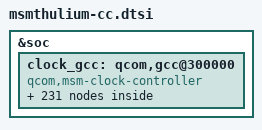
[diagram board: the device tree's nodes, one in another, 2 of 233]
/* Copyright (c) 2014, The Linux Foundation. All rights reserved.
 *
 * This program is free software; you can redistribute it and/or modify
 * it under the terms of the GNU General Public License version 2 and
 * only version 2 as published by the Free Software Foundation.
 *
 * This program is distributed in the hope that it will be useful,
 * but WITHOUT ANY WARRANTY; without even the implied warranty of
 * MERCHANTABILITY or FITNESS FOR A PARTICULAR PURPOSE.  See the
 * GNU General Public License for more details.
 */

#include <dt-bindings/clock/msm-clocks-thulium.h>
#include <dt-bindings/clock/msm-clocks-hwio-thulium.h>

&soc {
	clock_gcc: qcom,gcc@300000 {
		compatible = "qcom,msm-clock-controller";
		reg = <0x300000 0x8f010>;
		reg-names = "cc-base";
		#clock-cells = <1>;

		clock-names = "mmss_gcc_dbg_clk";
		clocks = <&clock_mmss clk_mmss_gcc_dbg_clk>;

		gcc_vdd_dig-supply = <&pmthulium_s1_corner>;
		qcom,regulator-names = "gcc_vdd_dig";

		gcc_vdd_dig: gcc_vdd_dig {
			compatible = "qcom,simple-vdd-class";
			qcom,regulators = <&pmthulium_s1_corner>;
			qcom,uV-levels =
				<RPM_REGULATOR_CORNER_NONE>,
				<RPM_REGULATOR_CORNER_SVS_SOC>,
				<RPM_REGULATOR_CORNER_SVS_SOC>,
				<RPM_REGULATOR_CORNER_NOMINAL>,
				<RPM_REGULATOR_CORNER_SUPER_TURBO>;
		};
	};
};

&clock_gcc {
	gcc_mmss_gcc_dbg_clk: gcc_mmss_gcc_dbg_clk {
		compatible = "qcom,ext-clk";
		qcom,clock-names = "mmss_gcc_dbg_clk";
		qcom,clk-flags = <0x4000>;
	};

	ce1_clk: ce1_clk {
		compatible = "qcom,rpm-clk";
		qcom,res-type = "ce";
		qcom,res-id = <0>;
		qcom,key = "KHz";
		qcom,rpm-peer = <&ce1_a_clk>;
	};

	ce1_a_clk: ce1_a_clk {
		compatible = "qcom,rpm-a-clk";
		qcom,res-type = "ce";
		qcom,res-id = <0>;
		qcom,key = "KHz";
		qcom,rpm-peer = <&ce1_clk>;
	};

	cxo_clk_src: cxo_clk_src {
		compatible = "qcom,rpm-branch-clk";
		qcom,res-type = "clk0";
		qcom,res-id = <0>;
		qcom,key = "Enab";
		qcom,rpm-peer = <&cxo_clk_src_ao>;
		qcom,rcg-init-rate = <19200000>;
	};

	cxo_clk_src_ao: cxo_clk_src_ao {
		compatible = "qcom,rpm-branch-a-clk";
		qcom,res-type = "clk0";
		qcom,res-id = <0>;
		qcom,key = "Enab";
		qcom,rpm-peer = <&cxo_clk_src>;
		qcom,rcg-init-rate = <19200000>;
	};

	pnoc_clk: pnoc_clk {
		compatible = "qcom,rpm-clk";
		qcom,res-type = "clk1";
		qcom,res-id = <0>;
		qcom,key = "KHz";
		qcom,rpm-peer = <&pnoc_a_clk>;
	};

	pnoc_a_clk: pnoc_a_clk {
		compatible = "qcom,rpm-a-clk";
		qcom,res-type = "clk1";
		qcom,res-id = <0>;
		qcom,key = "KHz";
		qcom,rpm-peer = <&pnoc_clk>;
	};

	bimc_clk: bimc_clk {
		compatible = "qcom,rpm-clk";
		qcom,res-type = "clk2";
		qcom,res-id = <0>;
		qcom,key = "KHz";
		qcom,rpm-peer = <&bimc_a_clk>;
	};

	bimc_a_clk: bimc_a_clk {
		compatible = "qcom,rpm-a-clk";
		qcom,res-type = "clk2";
		qcom,res-id = <0>;
		qcom,key = "KHz";
		qcom,rpm-peer = <&bimc_clk>;
	};

	cnoc_clk: cnoc_clk {
		compatible = "qcom,rpm-clk";
		qcom,res-type = "clk1";
		qcom,res-id = <2>;
		qcom,key = "KHz";
		qcom,rpm-peer = <&cnoc_a_clk>;
	};

	cnoc_a_clk: cnoc_a_clk {
		compatible = "qcom,rpm-a-clk";
		qcom,res-type = "clk1";
		qcom,res-id = <2>;
		qcom,key = "KHz";
		qcom,rpm-peer = <&cnoc_clk>;
	};

	snoc_clk: snoc_clk {
		compatible = "qcom,rpm-clk";
		qcom,res-type = "clk1";
		qcom,res-id = <1>;
		qcom,key = "KHz";
		qcom,rpm-peer = <&snoc_a_clk>;
	};

	snoc_a_clk: snoc_a_clk {
		compatible = "qcom,rpm-a-clk";
		qcom,res-type = "clk1";
		qcom,res-id = <1>;
		qcom,key = "KHz";
		qcom,rpm-peer = <&snoc_clk>;
	};

	aggre1_noc_clk: aggre1_noc_clk {
		compatible = "qcom,rpm-branch-clk";
		qcom,res-type = "aggr";
		qcom,res-id = <1>;
		qcom,key = "Enab";
		qcom,rpm-peer = <&aggre1_noc_a_clk>;
		qcom,rcg-init-rate = <1000>;
	};

	aggre1_noc_a_clk: aggre1_noc_a_clk {
		compatible = "qcom,rpm-branch-a-clk";
		qcom,res-type = "aggr";
		qcom,res-id = <1>;
		qcom,key = "Enab";
		qcom,rpm-peer = <&aggre1_noc_clk>;
		qcom,rcg-init-rate = <1000>;
	};

	aggre2_noc_clk: aggre2_noc_clk {
		compatible = "qcom,rpm-branch-clk";
		qcom,res-type = "aggr";
		qcom,res-id = <2>;
		qcom,key = "Enab";
		qcom,rpm-peer = <&aggre2_noc_a_clk>;
		qcom,rcg-init-rate = <1000>;
	};

	aggre2_noc_a_clk: aggre2_noc_a_clk {
		compatible = "qcom,rpm-branch-a-clk";
		qcom,res-type = "aggr";
		qcom,res-id = <2>;
		qcom,key = "Enab";
		qcom,rpm-peer = <&aggre2_noc_clk>;
		qcom,rcg-init-rate = <1000>;
	};

	bb_clk1: bb_clk1 {
		compatible = "qcom,rpm-branch-clk";
		qcom,res-type = "clka";
		qcom,res-id = <1>;
		qcom,key = "swen";
		qcom,rpm-peer = <&bb_clk1_ao>;
		qcom,rcg-init-rate = <1000>;
	};

	bb_clk1_ao: bb_clk1_ao {
		compatible = "qcom,rpm-branch-a-clk";
		qcom,res-type = "clka";
		qcom,res-id = <1>;
		qcom,key = "swen";
		qcom,rpm-peer = <&bb_clk1>;
		qcom,rcg-init-rate = <1000>;
	};

	bb_clk1_pin: bb_clk1_pin {
		compatible = "qcom,rpm-branch-clk";
		qcom,res-type = "clka";
		qcom,res-id = <1>;
		qcom,key = "pccb";
		qcom,rpm-peer = <&bb_clk1_pin_ao>;
		qcom,rcg-init-rate = <1000>;
	};

	bb_clk1_pin_ao: bb_clk1_pin_ao {
		compatible = "qcom,rpm-branch-a-clk";
		qcom,res-type = "clka";
		qcom,res-id = <1>;
		qcom,key = "pccb";
		qcom,rpm-peer = <&bb_clk1_pin>;
		qcom,rcg-init-rate = <1000>;
	};

	bb_clk2: bb_clk2 {
		compatible = "qcom,rpm-branch-clk";
		qcom,res-type = "clka";
		qcom,res-id = <2>;
		qcom,key = "swen";
		qcom,rpm-peer = <&bb_clk2_ao>;
		qcom,rcg-init-rate = <1000>;
	};

	bb_clk2_ao: bb_clk2_ao {
		compatible = "qcom,rpm-branch-a-clk";
		qcom,res-type = "clka";
		qcom,res-id = <2>;
		qcom,key = "swen";
		qcom,rpm-peer = <&bb_clk2>;
		qcom,rcg-init-rate = <1000>;
	};

	bb_clk2_pin: bb_clk2_pin {
		compatible = "qcom,rpm-branch-clk";
		qcom,res-type = "clka";
		qcom,res-id = <2>;
		qcom,key = "pccb";
		qcom,rpm-peer = <&bb_clk2_a_pin_ao>;
		qcom,rcg-init-rate = <1000>;
	};

	bb_clk2_a_pin_ao: bb_clk2_a_pin_ao {
		compatible = "qcom,rpm-branch-a-clk";
		qcom,res-type = "clka";
		qcom,res-id = <2>;
		qcom,key = "pccb";
		qcom,rpm-peer = <&bb_clk2_pin>;
		qcom,rcg-init-rate = <1000>;
	};

	bimc_msmbus_a_clk: bimc_msmbus_a_clk {
		compatible = "qcom,sw-vote-clk";
		qcom,parent = <&bimc_a_clk>;
		qcom,config-rate = <2147483647>;
	};

	bimc_msmbus_clk: bimc_msmbus_clk {
		compatible = "qcom,sw-vote-clk";
		qcom,parent = <&bimc_clk>;
		qcom,config-rate = <2147483647>;
	};

	cnoc_msmbus_a_clk: cnoc_msmbus_a_clk {
		compatible = "qcom,sw-vote-clk";
		qcom,parent = <&cnoc_a_clk>;
		qcom,config-rate = <2147483647>;
	};

	cnoc_msmbus_clk: cnoc_msmbus_clk {
		compatible = "qcom,sw-vote-clk";
		qcom,parent = <&cnoc_clk>;
		qcom,config-rate = <2147483647>;
	};

	cxo_dwc3_clk: cxo_dwc3_clk {
		compatible = "qcom,dummy-clk";
		qcom,parent = <&cxo_clk_src>;
	};

	cxo_lpm_clk: cxo_lpm_clk {
		compatible = "qcom,dummy-clk";
		qcom,parent = <&cxo_clk_src>;
	};

	cxo_otg_clk: cxo_otg_clk {
		compatible = "qcom,dummy-clk";
		qcom,parent = <&cxo_clk_src>;
	};

	cxo_pil_lpass_clk: cxo_pil_lpass_clk {
		compatible = "qcom,dummy-clk";
		qcom,parent = <&cxo_clk_src>;
	};

	div_clk1: div_clk1 {
		compatible = "qcom,rpm-branch-clk";
		qcom,res-type = "clka";
		qcom,res-id = <0xb>;
		qcom,key = "swen";
		qcom,rpm-peer = <&div_clk1_ao>;
		qcom,rcg-init-rate = <1000>;
	};

	div_clk1_ao: div_clk1_ao {
		compatible = "qcom,rpm-branch-a-clk";
		qcom,res-type = "clka";
		qcom,res-id = <0xb>;
		qcom,key = "swen";
		qcom,rpm-peer = <&div_clk1>;
		qcom,rcg-init-rate = <1000>;
	};

	div_clk2: div_clk2 {
		compatible = "qcom,rpm-branch-clk";
		qcom,res-type = "clka";
		qcom,res-id = <0xc>;
		qcom,key = "swen";
		qcom,rpm-peer = <&div_clk2_ao>;
		qcom,rcg-init-rate = <1000>;
	};

	div_clk2_ao: div_clk2_ao {
		compatible = "qcom,rpm-branch-a-clk";
		qcom,res-type = "clka";
		qcom,res-id = <0xc>;
		qcom,key = "swen";
		qcom,rpm-peer = <&div_clk2>;
		qcom,rcg-init-rate = <1000>;
	};

	div_clk3: div_clk3 {
		compatible = "qcom,rpm-branch-clk";
		qcom,res-type = "clka";
		qcom,res-id = <0xd>;
		qcom,key = "swen";
		qcom,rpm-peer = <&div_clk3_ao>;
		qcom,rcg-init-rate = <1000>;
	};

	div_clk3_ao: div_clk3_ao {
		compatible = "qcom,rpm-branch-a-clk";
		qcom,res-type = "clka";
		qcom,res-id = <0xd>;
		qcom,key = "swen";
		qcom,rpm-peer = <&div_clk3>;
		qcom,rcg-init-rate = <1000>;
	};

	ipa_clk: ipa_clk {
		compatible = "qcom,rpm-clk";
		qcom,res-type = "ipa";
		qcom,res-id = <0>;
		qcom,key = "KHz";
		qcom,rpm-peer = <&ipa_a_clk>;
	};

	ipa_a_clk: ipa_a_clk {
		compatible = "qcom,rpm-a-clk";
		qcom,res-type = "ipa";
		qcom,res-id = <0>;
		qcom,key = "KHz";
		qcom,rpm-peer = <&ipa_clk>;
	};

	ln_bb_clk: ln_bb_clk {
		compatible = "qcom,rpm-branch-clk";
		qcom,res-type = "clka";
		qcom,res-id = <8>;
		qcom,key = "swen";
		qcom,rpm-peer = <&ln_bb_a_clk>;
		qcom,rcg-init-rate = <1000>;
	};

	ln_bb_a_clk: ln_bb_a_clk {
		compatible = "qcom,rpm-branch-a-clk";
		qcom,res-type = "clka";
		qcom,res-id = <8>;
		qcom,key = "swen";
		qcom,rpm-peer = <&ln_bb_clk>;
		qcom,rcg-init-rate = <1000>;
	};

	mcd_ce1_clk: mcd_ce1_clk {
		compatible = "qcom,sw-vote-clk";
		qcom,parent = <&ce1_clk>;
		qcom,config-rate = <85710000>;
	};

	pnoc_keepalive_a_clk: pnoc_keepalive_a_clk {
		compatible = "qcom,sw-vote-clk";
		qcom,parent = <&pnoc_a_clk>;
		qcom,always-on;
		qcom,config-rate = <19200000>;
	};

	pnoc_msmbus_a_clk: pnoc_msmbus_a_clk {
		compatible = "qcom,sw-vote-clk";
		qcom,parent = <&pnoc_a_clk>;
		qcom,config-rate = <2147483647>;
	};

	pnoc_msmbus_clk: pnoc_msmbus_clk {
		compatible = "qcom,sw-vote-clk";
		qcom,parent = <&pnoc_clk>;
		qcom,config-rate = <2147483647>;
	};

	pnoc_pm_clk: pnoc_pm_clk {
		compatible = "qcom,sw-vote-clk";
		qcom,parent = <&pnoc_clk>;
		qcom,config-rate = <2147483647>;
	};

	pnoc_sps_clk: pnoc_sps_clk {
		compatible = "qcom,sw-vote-clk";
		qcom,parent = <&pnoc_clk>;
		qcom,config-rate = <0>;
	};

	qcedev_ce1_clk: qcedev_ce1_clk {
		compatible = "qcom,sw-vote-clk";
		qcom,parent = <&ce1_clk>;
		qcom,config-rate = <85710000>;
	};

	qcrypto_ce1_clk: qcrypto_ce1_clk {
		compatible = "qcom,sw-vote-clk";
		qcom,parent = <&ce1_clk>;
		qcom,config-rate = <85710000>;
	};

	qdss_clk: qdss_clk {
		compatible = "qcom,rpm-clk";
		qcom,res-type = "clk0";
		qcom,res-id = <1>;
		qcom,key = "STAT";
		qcom,rpm-peer = <&qdss_a_clk>;
	};

	qdss_a_clk: qdss_a_clk {
		compatible = "qcom,rpm-a-clk";
		qcom,res-type = "clk0";
		qcom,res-id = <1>;
		qcom,key = "STAT";
		qcom,rpm-peer = <&qdss_clk>;
	};

	qseecom_ce1_clk: qseecom_ce1_clk {
		compatible = "qcom,sw-vote-clk";
		qcom,parent = <&ce1_clk>;
		qcom,config-rate = <85710000>;
	};

	rf_clk1: rf_clk1 {
		compatible = "qcom,rpm-branch-clk";
		qcom,res-type = "clka";
		qcom,res-id = <4>;
		qcom,key = "swen";
		qcom,rpm-peer = <&rf_clk1_ao>;
		qcom,rcg-init-rate = <1000>;
	};

	rf_clk1_ao: rf_clk1_ao {
		compatible = "qcom,rpm-branch-a-clk";
		qcom,res-type = "clka";
		qcom,res-id = <4>;
		qcom,key = "swen";
		qcom,rpm-peer = <&rf_clk1>;
		qcom,rcg-init-rate = <1000>;
	};

	rf_clk1_pin: rf_clk1_pin {
		compatible = "qcom,rpm-branch-clk";
		qcom,res-type = "clka";
		qcom,res-id = <4>;
		qcom,key = "pccb";
		qcom,rpm-peer = <&rf_clk1_a_pin_ao>;
		qcom,rcg-init-rate = <1000>;
	};

	rf_clk1_a_pin_ao: rf_clk1_a_pin_ao {
		compatible = "qcom,rpm-branch-a-clk";
		qcom,res-type = "clka";
		qcom,res-id = <4>;
		qcom,key = "pccb";
		qcom,rpm-peer = <&rf_clk1_pin>;
		qcom,rcg-init-rate = <1000>;
	};

	rf_clk2: rf_clk2 {
		compatible = "qcom,rpm-branch-clk";
		qcom,res-type = "clka";
		qcom,res-id = <5>;
		qcom,key = "swen";
		qcom,rpm-peer = <&rf_clk2_ao>;
		qcom,rcg-init-rate = <1000>;
	};

	rf_clk2_ao: rf_clk2_ao {
		compatible = "qcom,rpm-branch-a-clk";
		qcom,res-type = "clka";
		qcom,res-id = <5>;
		qcom,key = "swen";
		qcom,rpm-peer = <&rf_clk2>;
		qcom,rcg-init-rate = <1000>;
	};

	rf_clk2_pin: rf_clk2_pin {
		compatible = "qcom,rpm-branch-clk";
		qcom,res-type = "clka";
		qcom,res-id = <5>;
		qcom,key = "pccb";
		qcom,rpm-peer = <&rf_clk2_a_pin_ao>;
		qcom,rcg-init-rate = <1000>;
	};

	rf_clk2_a_pin_ao: rf_clk2_a_pin_ao {
		compatible = "qcom,rpm-branch-a-clk";
		qcom,res-type = "clka";
		qcom,res-id = <5>;
		qcom,key = "pccb";
		qcom,rpm-peer = <&rf_clk2_pin>;
		qcom,rcg-init-rate = <1000>;
	};

	scm_ce1_clk: scm_ce1_clk {
		compatible = "qcom,sw-vote-clk";
		qcom,parent = <&ce1_clk>;
		qcom,config-rate = <85710000>;
	};

	snoc_msmbus_a_clk: snoc_msmbus_a_clk {
		compatible = "qcom,sw-vote-clk";
		qcom,parent = <&snoc_a_clk>;
		qcom,config-rate = <2147483647>;
	};

	snoc_msmbus_clk: snoc_msmbus_clk {
		compatible = "qcom,sw-vote-clk";
		qcom,parent = <&snoc_clk>;
		qcom,config-rate = <2147483647>;
	};

	gcc_ce1_ahb_m_clk: gcc_ce1_ahb_m_clk {
		compatible = "qcom,dummy-clk";
	};

	gcc_ce1_axi_m_clk: gcc_ce1_axi_m_clk {
		compatible = "qcom,dummy-clk";
	};

	gcc_mmss_bimc_gfx_m_clk: gcc_mmss_bimc_gfx_m_clk {
		compatible = "qcom,dummy-clk";
	};

	gpll0: gpll0 {
		compatible = "qcom,sleep-active-pll";
		qcom,en-offset = <GCC_APCS_GPLL_ENA_VOTE>;
		qcom,en-bit = <0>;
		qcom,status-offset = <GCC_GPLL0_MODE>;
		qcom,status-bit = <30>;
		qcom,peer = <&gpll0_ao>;
		qcom,pll-config-rate = <600000000>;
		qcom,parent = <&cxo_clk_src>;
	};

	gpll0_ao: gpll0_ao {
		compatible = "qcom,active-only-pll";
		qcom,en-offset = <GCC_APCS_GPLL_ENA_VOTE>;
		qcom,en-bit = <0>;
		qcom,status-offset = <GCC_GPLL0_MODE>;
		qcom,status-bit = <30>;
		qcom,peer = <&gpll0>;
		qcom,pll-config-rate = <600000000>;
		qcom,parent = <&cxo_clk_src_ao>;
	};

	gpll0_out_main: gpll0_out_main {
		compatible = "qcom,ext-clk";
		qcom,parent = <&gpll0>;
	};

	gpll4: gpll4 {
		compatible = "qcom,votable-pll";
		qcom,en-offset = <GCC_APCS_GPLL_ENA_VOTE>;
		qcom,en-bit = <4>;
		qcom,status-offset = <GCC_GPLL4_MODE>;
		qcom,status-bit = <30>;
		qcom,pll-config-rate = <1536000000>;
		qcom,parent = <&cxo_clk_src>;
		qcom,supply-group = <&gcc_vdd_dig>;
		qcom,clk-fmax =
			<FMAX_LOWER 400000000>,
			<FMAX_LOW 800000000>,
			<FMAX_NOM 1600000000>,
			<FMAX_TURBO 1600000000>;
	};

	gpll4_out_main: gpll4_out_main {
		compatible = "qcom,ext-clk";
		qcom,parent = <&gpll4>;
	};

	ufs_axi_clk_src {
		qcom,freq-tbl =
			< 100000000 6 0 0 0 &gpll0_out_main>,
			< 200000000 3 0 0 0 &gpll0_out_main>,
			< 240000000 2 50 0 0 &gpll0_out_main>;
	};

	ufs_axi_clk_src: ufs_axi_clk_src {
		compatible = "qcom,rcg-mn";
		qcom,base-offset = <GCC_UFS_AXI_CMD_RCGR>;
		qcom,parents =
			<    0 &cxo_clk_src>,
			<    1 &gpll0_out_main>;
		qcom,supply-group = <&gcc_vdd_dig>;
		qcom,clk-fmax =
			<FMAX_LOWER 19200000>,
			<FMAX_LOW 100000000>,
			<FMAX_NOM 200000000>,
			<FMAX_TURBO 240000000>;
	};

	pcie_aux_clk_src {
		qcom,freq-tbl =
			<   1010526 19 0 0 0 &cxo_clk_src>;
	};

	pcie_aux_clk_src: pcie_aux_clk_src {
		compatible = "qcom,rcg-mn";
		qcom,base-offset = <GCC_PCIE_AUX_CMD_RCGR>;
		qcom,parents =
			<    0 &cxo_clk_src>;
		qcom,supply-group = <&gcc_vdd_dig>;
		qcom,clk-fmax =
			<FMAX_LOWER 1011000>,
			<FMAX_LOW 1011000>,
			<FMAX_NOM 1011000>,
			<FMAX_TURBO 1011000>;
	};

	usb30_master_clk_src {
		qcom,freq-tbl =
			< 125000000 1 0 5 24 &gpll0_out_main>;
	};

	usb30_master_clk_src: usb30_master_clk_src {
		compatible = "qcom,rcg-mn";
		qcom,base-offset = <GCC_USB30_MASTER_CMD_RCGR>;
		qcom,parents =
			<    0 &cxo_clk_src>,
			<    1 &gpll0_out_main>;
		qcom,supply-group = <&gcc_vdd_dig>;
		qcom,clk-fmax =
			<FMAX_LOWER 60000000>,
			<FMAX_LOW 125000000>,
			<FMAX_NOM 125000000>,
			<FMAX_TURBO 125000000>;
	};

	usb20_master_clk_src {
		qcom,freq-tbl =
			< 120000000 5 0 0 0 &gpll0_out_main>;
	};

	usb20_master_clk_src: usb20_master_clk_src {
		compatible = "qcom,rcg-mn";
		qcom,base-offset = <GCC_USB20_MASTER_CMD_RCGR>;
		qcom,parents =
			<    0 &cxo_clk_src>,
			<    1 &gpll0_out_main>;
		qcom,supply-group = <&gcc_vdd_dig>;
		qcom,clk-fmax =
			<FMAX_LOWER 19200000>,
			<FMAX_LOW 60000000>,
			<FMAX_NOM 120000000>,
			<FMAX_TURBO 120000000>;
	};

	ufs_ice_core_clk_src {
		qcom,freq-tbl =
			< 19200000 1 0 0 0 &cxo_clk_src>,
			< 150000000 4 0 0 0 &gpll0_out_main>,
			< 300000000 2 0 0 0 &gpll0_out_main>;
	};

	ufs_ice_core_clk_src: ufs_ice_core_clk_src {
		compatible = "qcom,rcg-hid";
		qcom,base-offset = <GCC_UFS_ICE_CORE_CMD_RCGR>;
		qcom,parents =
			<    0 &cxo_clk_src>,
			<    1 &gpll0_out_main>;
		qcom,supply-group = <&gcc_vdd_dig>;
		qcom,clk-fmax =
			<FMAX_LOWER 19200000>,
			<FMAX_LOW 150000000>,
			<FMAX_NOM 300000000>,
			<FMAX_TURBO 300000000>;
	};

	blsp1_qup1_i2c_apps_clk_src {
		qcom,freq-tbl =
			<  19200000 1 0 0 0 &cxo_clk_src>,
			<  50000000 12 0 0 0 &gpll0_out_main>;
	};

	blsp1_qup1_i2c_apps_clk_src: blsp1_qup1_i2c_apps_clk_src {
		compatible = "qcom,rcg-hid";
		qcom,base-offset = <GCC_BLSP1_QUP1_I2C_APPS_CMD_RCGR>;
		qcom,parents =
			<    0 &cxo_clk_src>,
			<    1 &gpll0_out_main>;
		qcom,supply-group = <&gcc_vdd_dig>;
		qcom,clk-fmax =
			<FMAX_LOWER 19200000>,
			<FMAX_LOW 50000000>,
			<FMAX_NOM 50000000>,
			<FMAX_TURBO 50000000>;
	};

	blsp1_qup1_spi_apps_clk_src {
		qcom,freq-tbl =
			<    960000 10 0 1 2 &cxo_clk_src>,
			<   4800000 4 0 0 0 &cxo_clk_src>,
			<   9600000 2 0 0 0 &cxo_clk_src>,
			<  15000000 10 0 1 4 &gpll0_out_main>,
			<  25000000 12 0 1 2 &gpll0_out_main>,
			<  50000000 12 0 0 0 &gpll0_out_main>;
	};

	blsp1_qup1_spi_apps_clk_src: blsp1_qup1_spi_apps_clk_src {
		compatible = "qcom,rcg-mn";
		qcom,base-offset = <GCC_BLSP1_QUP1_SPI_APPS_CMD_RCGR>;
		qcom,parents =
			<    0 &cxo_clk_src>,
			<    1 &gpll0_out_main>;
		qcom,supply-group = <&gcc_vdd_dig>;
		qcom,clk-fmax =
			<FMAX_LOWER 19200000>,
			<FMAX_LOW 25000000>,
			<FMAX_NOM 50000000>,
			<FMAX_TURBO 50000000>;
	};

	blsp1_qup2_i2c_apps_clk_src {
		qcom,freq-tbl =
			<   19200000 1 0 0 0 &cxo_clk_src>,
			<  50000000 12 0 0 0 &gpll0_out_main>;
	};

	blsp1_qup2_i2c_apps_clk_src: blsp1_qup2_i2c_apps_clk_src {
		compatible = "qcom,rcg-hid";
		qcom,base-offset = <GCC_BLSP1_QUP2_I2C_APPS_CMD_RCGR>;
		qcom,parents =
			<    0 &cxo_clk_src>,
			<    1 &gpll0_out_main>;
		qcom,supply-group = <&gcc_vdd_dig>;
		qcom,clk-fmax =
			<FMAX_LOWER 19200000>,
			<FMAX_LOW 50000000>,
			<FMAX_NOM 50000000>,
			<FMAX_TURBO 50000000>;
	};

	blsp1_qup2_spi_apps_clk_src {
		qcom,freq-tbl =
			<    960000 10 0 1 2 &cxo_clk_src>,
			<   4800000 4 0 0 0 &cxo_clk_src>,
			<   9600000 2 0 0 0 &cxo_clk_src>,
			<  15000000 10 0 1 4 &gpll0_out_main>,
			<  25000000 12 0 1 2 &gpll0_out_main>,
			<  50000000 12 0 0 0 &gpll0_out_main>;
	};

	blsp1_qup2_spi_apps_clk_src: blsp1_qup2_spi_apps_clk_src {
		compatible = "qcom,rcg-mn";
		qcom,base-offset = <GCC_BLSP1_QUP2_SPI_APPS_CMD_RCGR>;
		qcom,parents =
			<    0 &cxo_clk_src>,
			<    1 &gpll0_out_main>;
		qcom,supply-group = <&gcc_vdd_dig>;
		qcom,clk-fmax =
			<FMAX_LOWER 19200000>,
			<FMAX_LOW 25000000>,
			<FMAX_NOM 50000000>,
			<FMAX_TURBO 50000000>;
	};

	blsp1_qup3_i2c_apps_clk_src {
		qcom,freq-tbl =
			<   19200000 1 0 0 0 &cxo_clk_src>,
			<  50000000 12 0 0 0 &gpll0_out_main>;
	};

	blsp1_qup3_i2c_apps_clk_src: blsp1_qup3_i2c_apps_clk_src {
		compatible = "qcom,rcg-hid";
		qcom,base-offset = <GCC_BLSP1_QUP3_I2C_APPS_CMD_RCGR>;
		qcom,parents =
			<    0 &cxo_clk_src>,
			<    1 &gpll0_out_main>;
		qcom,supply-group = <&gcc_vdd_dig>;
		qcom,clk-fmax =
			<FMAX_LOWER 19200000>,
			<FMAX_LOW 50000000>,
			<FMAX_NOM 50000000>,
			<FMAX_TURBO 50000000>;
	};

	blsp1_qup3_spi_apps_clk_src {
		qcom,freq-tbl =
			<    960000 10 0 1 2 &cxo_clk_src>,
			<   4800000 4 0 0 0 &cxo_clk_src>,
			<   9600000 2 0 0 0 &cxo_clk_src>,
			<  15000000 10 0 1 4 &gpll0_out_main>,
			<  25000000 12 0 1 2 &gpll0_out_main>,
			<  50000000 12 0 0 0 &gpll0_out_main>;
	};

	blsp1_qup3_spi_apps_clk_src: blsp1_qup3_spi_apps_clk_src {
		compatible = "qcom,rcg-mn";
		qcom,base-offset = <GCC_BLSP1_QUP3_SPI_APPS_CMD_RCGR>;
		qcom,parents =
			<    0 &cxo_clk_src>,
			<    1 &gpll0_out_main>;
		qcom,supply-group = <&gcc_vdd_dig>;
		qcom,clk-fmax =
			<FMAX_LOWER 19200000>,
			<FMAX_LOW 25000000>,
			<FMAX_NOM 50000000>,
			<FMAX_TURBO 50000000>;
	};

	blsp1_qup4_i2c_apps_clk_src {
		qcom,freq-tbl =
			<   19200000 1 0 0 0 &cxo_clk_src>,
			<  50000000 12 0 0 0 &gpll0_out_main>;
	};

	blsp1_qup4_i2c_apps_clk_src: blsp1_qup4_i2c_apps_clk_src {
		compatible = "qcom,rcg-hid";
		qcom,base-offset = <GCC_BLSP1_QUP4_I2C_APPS_CMD_RCGR>;
		qcom,parents =
			<    0 &cxo_clk_src>,
			<    1 &gpll0_out_main>;
		qcom,supply-group = <&gcc_vdd_dig>;
		qcom,clk-fmax =
			<FMAX_LOWER 19200000>,
			<FMAX_LOW 50000000>,
			<FMAX_NOM 50000000>,
			<FMAX_TURBO 50000000>;
	};

	blsp1_qup4_spi_apps_clk_src {
		qcom,freq-tbl =
			<    960000 10 0 1 2 &cxo_clk_src>,
			<   4800000 4 0 0 0 &cxo_clk_src>,
			<   9600000 2 0 0 0 &cxo_clk_src>,
			<  15000000 10 0 1 4 &gpll0_out_main>,
			<  25000000 12 0 1 2 &gpll0_out_main>,
			<  50000000 12 0 0 0 &gpll0_out_main>;
	};

	blsp1_qup4_spi_apps_clk_src: blsp1_qup4_spi_apps_clk_src {
		compatible = "qcom,rcg-mn";
		qcom,base-offset = <GCC_BLSP1_QUP4_SPI_APPS_CMD_RCGR>;
		qcom,parents =
			<    0 &cxo_clk_src>,
			<    1 &gpll0_out_main>;
		qcom,supply-group = <&gcc_vdd_dig>;
		qcom,clk-fmax =
			<FMAX_LOWER 19200000>,
			<FMAX_LOW 25000000>,
			<FMAX_NOM 50000000>,
			<FMAX_TURBO 50000000>;
	};

	blsp1_qup5_i2c_apps_clk_src {
		qcom,freq-tbl =
			<   19200000 1 0 0 0 &cxo_clk_src>,
			<  50000000 12 0 0 0 &gpll0_out_main>;
	};

	blsp1_qup5_i2c_apps_clk_src: blsp1_qup5_i2c_apps_clk_src {
		compatible = "qcom,rcg-hid";
		qcom,base-offset = <GCC_BLSP1_QUP5_I2C_APPS_CMD_RCGR>;
		qcom,parents =
			<    0 &cxo_clk_src>,
			<    1 &gpll0_out_main>;
		qcom,supply-group = <&gcc_vdd_dig>;
		qcom,clk-fmax =
			<FMAX_LOWER 19200000>,
			<FMAX_LOW 50000000>,
			<FMAX_NOM 50000000>,
			<FMAX_TURBO 50000000>;
	};

	blsp1_qup5_spi_apps_clk_src {
		qcom,freq-tbl =
			<    960000 10 0 1 2 &cxo_clk_src>,
			<   4800000 4 0 0 0 &cxo_clk_src>,
			<   9600000 2 0 0 0 &cxo_clk_src>,
			<  15000000 10 0 1 4 &gpll0_out_main>,
			<  25000000 12 0 1 2 &gpll0_out_main>,
			<  50000000 12 0 0 0 &gpll0_out_main>;
	};

	blsp1_qup5_spi_apps_clk_src: blsp1_qup5_spi_apps_clk_src {
		compatible = "qcom,rcg-mn";
		qcom,base-offset = <GCC_BLSP1_QUP5_SPI_APPS_CMD_RCGR>;
		qcom,parents =
			<    0 &cxo_clk_src>,
			<    1 &gpll0_out_main>;
		qcom,supply-group = <&gcc_vdd_dig>;
		qcom,clk-fmax =
			<FMAX_LOWER 19200000>,
			<FMAX_LOW 25000000>,
			<FMAX_NOM 50000000>,
			<FMAX_TURBO 50000000>;
	};

	blsp1_qup6_i2c_apps_clk_src {
		qcom,freq-tbl =
			<   19200000 1 0 0 0 &cxo_clk_src>,
			<  50000000 12 0 0 0 &gpll0_out_main>;
	};

	blsp1_qup6_i2c_apps_clk_src: blsp1_qup6_i2c_apps_clk_src {
		compatible = "qcom,rcg-hid";
		qcom,base-offset = <GCC_BLSP1_QUP6_I2C_APPS_CMD_RCGR>;
		qcom,parents =
			<    0 &cxo_clk_src>,
			<    1 &gpll0_out_main>;
		qcom,supply-group = <&gcc_vdd_dig>;
		qcom,clk-fmax =
			<FMAX_LOWER 19200000>,
			<FMAX_LOW 50000000>,
			<FMAX_NOM 50000000>,
			<FMAX_TURBO 50000000>;
	};

	blsp1_qup6_spi_apps_clk_src {
		qcom,freq-tbl =
			<    960000 10 0 1 2 &cxo_clk_src>,
			<   4800000 4 0 0 0 &cxo_clk_src>,
			<   9600000 2 0 0 0 &cxo_clk_src>,
			<  15000000 10 0 1 4 &gpll0_out_main>,
			<  25000000 12 0 1 2 &gpll0_out_main>,
			<  50000000 12 0 0 0 &gpll0_out_main>;
	};

	blsp1_qup6_spi_apps_clk_src: blsp1_qup6_spi_apps_clk_src {
		compatible = "qcom,rcg-mn";
		qcom,base-offset = <GCC_BLSP1_QUP6_SPI_APPS_CMD_RCGR>;
		qcom,parents =
			<    0 &cxo_clk_src>,
			<    1 &gpll0_out_main>;
		qcom,supply-group = <&gcc_vdd_dig>;
		qcom,clk-fmax =
			<FMAX_LOWER 19200000>,
			<FMAX_LOW 25000000>,
			<FMAX_NOM 50000000>,
			<FMAX_TURBO 50000000>;
	};

	blsp1_uart1_apps_clk_src {
		qcom,freq-tbl =
			<   3686400 1 0 96 15625 &gpll0_out_main>,
			<   7372800 1 0 192 15625 &gpll0_out_main>,
			<  14745600 1 0 384 15625 &gpll0_out_main>,
			<  16000000 5 0 2 15 &gpll0_out_main>,
			<  24000000 5 0 1 5 &gpll0_out_main>,
			<  32000000 1 0 4 75 &gpll0_out_main>,
			<  40000000 15 0 0 0 &gpll0_out_main>,
			<  46400000 1 0 29 375 &gpll0_out_main>,
			<  48000000 12 50 0 0 &gpll0_out_main>,
			<  51200000 1 0 32 375 &gpll0_out_main>,
			<  56000000 1 0 7 75 &gpll0_out_main>,
			<  58982400 1 0 1536 15625 &gpll0_out_main>,
			<  60000000 10 0 0 0 &gpll0_out_main>,
			<  63160000 9 50 0 0 &gpll0_out_main>;
	};

	blsp1_uart1_apps_clk_src: blsp1_uart1_apps_clk_src {
		compatible = "qcom,rcg-mn";
		qcom,base-offset = <GCC_BLSP1_UART1_APPS_CMD_RCGR>;
		qcom,parents =
			<    0 &cxo_clk_src>,
			<    1 &gpll0_out_main>;
		qcom,supply-group = <&gcc_vdd_dig>;
		qcom,clk-fmax =
			<FMAX_LOWER 19200000>,
			<FMAX_LOW 31580000>,
			<FMAX_NOM 63160000>,
			<FMAX_TURBO 63160000>;
	};

	blsp1_uart2_apps_clk_src {
		qcom,freq-tbl =
			<   3686400 1 0 96 15625 &gpll0_out_main>,
			<   7372800 1 0 192 15625 &gpll0_out_main>,
			<  14745600 1 0 384 15625 &gpll0_out_main>,
			<  16000000 5 0 2 15 &gpll0_out_main>,
			<  24000000 5 0 1 5 &gpll0_out_main>,
			<  32000000 1 0 4 75 &gpll0_out_main>,
			<  40000000 15 0 0 0 &gpll0_out_main>,
			<  46400000 1 0 29 375 &gpll0_out_main>,
			<  48000000 12 50 0 0 &gpll0_out_main>,
			<  51200000 1 0 32 375 &gpll0_out_main>,
			<  56000000 1 0 7 75 &gpll0_out_main>,
			<  58982400 1 0 1536 15625 &gpll0_out_main>,
			<  60000000 10 0 0 0 &gpll0_out_main>,
			<  63160000 9 50 0 0 &gpll0_out_main>;
	};

	blsp1_uart2_apps_clk_src: blsp1_uart2_apps_clk_src {
		compatible = "qcom,rcg-mn";
		qcom,base-offset = <GCC_BLSP1_UART2_APPS_CMD_RCGR>;
		qcom,parents =
			<    0 &cxo_clk_src>,
			<    1 &gpll0_out_main>;
		qcom,supply-group = <&gcc_vdd_dig>;
		qcom,clk-fmax =
			<FMAX_LOWER 19200000>,
			<FMAX_LOW 31580000>,
			<FMAX_NOM 63160000>,
			<FMAX_TURBO 63160000>;
	};

	blsp1_uart3_apps_clk_src {
		qcom,freq-tbl =
			<   3686400 1 0 96 15625 &gpll0_out_main>,
			<   7372800 1 0 192 15625 &gpll0_out_main>,
			<  14745600 1 0 384 15625 &gpll0_out_main>,
			<  16000000 5 0 2 15 &gpll0_out_main>,
			<  24000000 5 0 1 5 &gpll0_out_main>,
			<  32000000 1 0 4 75 &gpll0_out_main>,
			<  40000000 15 0 0 0 &gpll0_out_main>,
			<  46400000 1 0 29 375 &gpll0_out_main>,
			<  48000000 12 50 0 0 &gpll0_out_main>,
			<  51200000 1 0 32 375 &gpll0_out_main>,
			<  56000000 1 0 7 75 &gpll0_out_main>,
			<  58982400 1 0 1536 15625 &gpll0_out_main>,
			<  60000000 10 0 0 0 &gpll0_out_main>,
			<  63160000 9 50 0 0 &gpll0_out_main>;
	};

	blsp1_uart3_apps_clk_src: blsp1_uart3_apps_clk_src {
		compatible = "qcom,rcg-mn";
		qcom,base-offset = <GCC_BLSP1_UART3_APPS_CMD_RCGR>;
		qcom,parents =
			<    0 &cxo_clk_src>,
			<    1 &gpll0_out_main>;
		qcom,supply-group = <&gcc_vdd_dig>;
		qcom,clk-fmax =
			<FMAX_LOWER 19200000>,
			<FMAX_LOW 31580000>,
			<FMAX_NOM 63160000>,
			<FMAX_TURBO 63160000>;
	};

	blsp1_uart4_apps_clk_src {
		qcom,freq-tbl =
			<   3686400 1 0 96 15625 &gpll0_out_main>,
			<   7372800 1 0 192 15625 &gpll0_out_main>,
			<  14745600 1 0 384 15625 &gpll0_out_main>,
			<  16000000 5 0 2 15 &gpll0_out_main>,
			<  24000000 5 0 1 5 &gpll0_out_main>,
			<  32000000 1 0 4 75 &gpll0_out_main>,
			<  40000000 15 0 0 0 &gpll0_out_main>,
			<  46400000 1 0 29 375 &gpll0_out_main>,
			<  48000000 12 50 0 0 &gpll0_out_main>,
			<  51200000 1 0 32 375 &gpll0_out_main>,
			<  56000000 1 0 7 75 &gpll0_out_main>,
			<  58982400 1 0 1536 15625 &gpll0_out_main>,
			<  60000000 10 0 0 0 &gpll0_out_main>,
			<  63160000 9 50 0 0 &gpll0_out_main>;
	};

	blsp1_uart4_apps_clk_src: blsp1_uart4_apps_clk_src {
		compatible = "qcom,rcg-mn";
		qcom,base-offset = <GCC_BLSP1_UART4_APPS_CMD_RCGR>;
		qcom,parents =
			<    0 &cxo_clk_src>,
			<    1 &gpll0_out_main>;
		qcom,supply-group = <&gcc_vdd_dig>;
		qcom,clk-fmax =
			<FMAX_LOWER 19200000>,
			<FMAX_LOW 31580000>,
			<FMAX_NOM 63160000>,
			<FMAX_TURBO 63160000>;
	};

	blsp1_uart5_apps_clk_src {
		qcom,freq-tbl =
			<   3686400 1 0 96 15625 &gpll0_out_main>,
			<   7372800 1 0 192 15625 &gpll0_out_main>,
			<  14745600 1 0 384 15625 &gpll0_out_main>,
			<  16000000 5 0 2 15 &gpll0_out_main>,
			<  24000000 5 0 1 5 &gpll0_out_main>,
			<  32000000 1 0 4 75 &gpll0_out_main>,
			<  40000000 15 0 0 0 &gpll0_out_main>,
			<  46400000 1 0 29 375 &gpll0_out_main>,
			<  48000000 12 50 0 0 &gpll0_out_main>,
			<  51200000 1 0 32 375 &gpll0_out_main>,
			<  56000000 1 0 7 75 &gpll0_out_main>,
			<  58982400 1 0 1536 15625 &gpll0_out_main>,
			<  60000000 10 0 0 0 &gpll0_out_main>,
			<  63160000 9 50 0 0 &gpll0_out_main>;
	};

	blsp1_uart5_apps_clk_src: blsp1_uart5_apps_clk_src {
		compatible = "qcom,rcg-mn";
		qcom,base-offset = <GCC_BLSP1_UART5_APPS_CMD_RCGR>;
		qcom,parents =
			<    0 &cxo_clk_src>,
			<    1 &gpll0_out_main>;
		qcom,supply-group = <&gcc_vdd_dig>;
		qcom,clk-fmax =
			<FMAX_LOWER 19200000>,
			<FMAX_LOW 31580000>,
			<FMAX_NOM 63160000>,
			<FMAX_TURBO 63160000>;
	};

	blsp1_uart6_apps_clk_src {
		qcom,freq-tbl =
			<   3686400 1 0 96 15625 &gpll0_out_main>,
			<   7372800 1 0 192 15625 &gpll0_out_main>,
			<  14745600 1 0 384 15625 &gpll0_out_main>,
			<  16000000 5 0 2 15 &gpll0_out_main>,
			<  24000000 5 0 1 5 &gpll0_out_main>,
			<  32000000 1 0 4 75 &gpll0_out_main>,
			<  40000000 15 0 0 0 &gpll0_out_main>,
			<  46400000 1 0 29 375 &gpll0_out_main>,
			<  48000000 12 50 0 0 &gpll0_out_main>,
			<  51200000 1 0 32 375 &gpll0_out_main>,
			<  56000000 1 0 7 75 &gpll0_out_main>,
			<  58982400 1 0 1536 15625 &gpll0_out_main>,
			<  60000000 10 0 0 0 &gpll0_out_main>,
			<  63160000 9 50 0 0 &gpll0_out_main>;
	};

	blsp1_uart6_apps_clk_src: blsp1_uart6_apps_clk_src {
		compatible = "qcom,rcg-mn";
		qcom,base-offset = <GCC_BLSP1_UART6_APPS_CMD_RCGR>;
		qcom,parents =
			<    0 &cxo_clk_src>,
			<    1 &gpll0_out_main>;
		qcom,supply-group = <&gcc_vdd_dig>;
		qcom,clk-fmax =
			<FMAX_LOWER 19200000>,
			<FMAX_LOW 31580000>,
			<FMAX_NOM 63160000>,
			<FMAX_TURBO 63160000>;
	};

	blsp2_qup1_i2c_apps_clk_src {
		qcom,freq-tbl =
			<   19200000 1 0 0 0 &cxo_clk_src>,
			<  50000000 12 0 0 0 &gpll0_out_main>;
	};

	blsp2_qup1_i2c_apps_clk_src: blsp2_qup1_i2c_apps_clk_src {
		compatible = "qcom,rcg-hid";
		qcom,base-offset = <GCC_BLSP2_QUP1_I2C_APPS_CMD_RCGR>;
		qcom,parents =
			<    0 &cxo_clk_src>,
			<    1 &gpll0_out_main>;
		qcom,supply-group = <&gcc_vdd_dig>;
		qcom,clk-fmax =
			<FMAX_LOWER 19200000>,
			<FMAX_LOW 50000000>,
			<FMAX_NOM 50000000>,
			<FMAX_TURBO 50000000>;
	};

	blsp2_qup1_spi_apps_clk_src {
		qcom,freq-tbl =
			<    960000 10 0 1 2 &cxo_clk_src>,
			<   4800000 4 0 0 0 &cxo_clk_src>,
			<   9600000 2 0 0 0 &cxo_clk_src>,
			<  15000000 10 0 1 4 &gpll0_out_main>,
			<  25000000 12 0 1 2 &gpll0_out_main>,
			<  50000000 12 0 0 0 &gpll0_out_main>;
	};

	blsp2_qup1_spi_apps_clk_src: blsp2_qup1_spi_apps_clk_src {
		compatible = "qcom,rcg-mn";
		qcom,base-offset = <GCC_BLSP2_QUP1_SPI_APPS_CMD_RCGR>;
		qcom,parents =
			<    0 &cxo_clk_src>,
			<    1 &gpll0_out_main>;
		qcom,supply-group = <&gcc_vdd_dig>;
		qcom,clk-fmax =
			<FMAX_LOWER 19200000>,
			<FMAX_LOW 25000000>,
			<FMAX_NOM 50000000>,
			<FMAX_TURBO 50000000>;
	};

	blsp2_qup2_i2c_apps_clk_src {
		qcom,freq-tbl =
			<   19200000 1 0 0 0 &cxo_clk_src>,
			<  50000000 12 0 0 0 &gpll0_out_main>;
	};

	blsp2_qup2_i2c_apps_clk_src: blsp2_qup2_i2c_apps_clk_src {
		compatible = "qcom,rcg-hid";
		qcom,base-offset = <GCC_BLSP2_QUP2_I2C_APPS_CMD_RCGR>;
		qcom,parents =
			<    0 &cxo_clk_src>,
			<    1 &gpll0_out_main>;
		qcom,supply-group = <&gcc_vdd_dig>;
		qcom,clk-fmax =
			<FMAX_LOWER 19200000>,
			<FMAX_LOW 50000000>,
			<FMAX_NOM 50000000>,
			<FMAX_TURBO 50000000>;
	};

	blsp2_qup2_spi_apps_clk_src {
		qcom,freq-tbl =
			<    960000 10 0 1 2 &cxo_clk_src>,
			<   4800000 4 0 0 0 &cxo_clk_src>,
			<   9600000 2 0 0 0 &cxo_clk_src>,
			<  15000000 10 0 1 4 &gpll0_out_main>,
			<  25000000 12 0 1 2 &gpll0_out_main>,
			<  50000000 12 0 0 0 &gpll0_out_main>;
	};

	blsp2_qup2_spi_apps_clk_src: blsp2_qup2_spi_apps_clk_src {
		compatible = "qcom,rcg-mn";
		qcom,base-offset = <GCC_BLSP2_QUP2_SPI_APPS_CMD_RCGR>;
		qcom,parents =
			<    0 &cxo_clk_src>,
			<    1 &gpll0_out_main>;
		qcom,supply-group = <&gcc_vdd_dig>;
		qcom,clk-fmax =
			<FMAX_LOWER 19200000>,
			<FMAX_LOW 25000000>,
			<FMAX_NOM 50000000>,
			<FMAX_TURBO 50000000>;
	};

	blsp2_qup3_i2c_apps_clk_src {
		qcom,freq-tbl =
			<   19200000 1 0 0 0 &cxo_clk_src>,
			<  50000000 12 0 0 0 &gpll0_out_main>;
	};

	blsp2_qup3_i2c_apps_clk_src: blsp2_qup3_i2c_apps_clk_src {
		compatible = "qcom,rcg-hid";
		qcom,base-offset = <GCC_BLSP2_QUP3_I2C_APPS_CMD_RCGR>;
		qcom,parents =
			<    0 &cxo_clk_src>,
			<    1 &gpll0_out_main>;
		qcom,supply-group = <&gcc_vdd_dig>;
		qcom,clk-fmax =
			<FMAX_LOWER 19200000>,
			<FMAX_LOW 50000000>,
			<FMAX_NOM 50000000>,
			<FMAX_TURBO 50000000>;
	};

	blsp2_qup3_spi_apps_clk_src {
		qcom,freq-tbl =
			<    960000 10 0 1 2 &cxo_clk_src>,
			<   4800000 4 0 0 0 &cxo_clk_src>,
			<   9600000 2 0 0 0 &cxo_clk_src>,
			<  15000000 10 0 1 4 &gpll0_out_main>,
			<  25000000 12 0 1 2 &gpll0_out_main>,
			<  50000000 12 0 0 0 &gpll0_out_main>;
	};

	blsp2_qup3_spi_apps_clk_src: blsp2_qup3_spi_apps_clk_src {
		compatible = "qcom,rcg-mn";
		qcom,base-offset = <GCC_BLSP2_QUP3_SPI_APPS_CMD_RCGR>;
		qcom,parents =
			<    0 &cxo_clk_src>,
			<    1 &gpll0_out_main>;
		qcom,supply-group = <&gcc_vdd_dig>;
		qcom,clk-fmax =
			<FMAX_LOWER 19200000>,
			<FMAX_LOW 25000000>,
			<FMAX_NOM 50000000>,
			<FMAX_TURBO 50000000>;
	};

	blsp2_qup4_i2c_apps_clk_src {
		qcom,freq-tbl =
			<   19200000 1 0 0 0 &cxo_clk_src>,
			<  50000000 12 0 0 0 &gpll0_out_main>;
	};

	blsp2_qup4_i2c_apps_clk_src: blsp2_qup4_i2c_apps_clk_src {
		compatible = "qcom,rcg-hid";
		qcom,base-offset = <GCC_BLSP2_QUP4_I2C_APPS_CMD_RCGR>;
		qcom,parents =
			<    0 &cxo_clk_src>,
			<    1 &gpll0_out_main>;
		qcom,supply-group = <&gcc_vdd_dig>;
		qcom,clk-fmax =
			<FMAX_LOWER 19200000>,
			<FMAX_LOW 50000000>,
			<FMAX_NOM 50000000>,
			<FMAX_TURBO 50000000>;
	};

	blsp2_qup4_spi_apps_clk_src {
		qcom,freq-tbl =
			<    960000 10 0 1 2 &cxo_clk_src>,
			<   4800000 4 0 0 0 &cxo_clk_src>,
			<   9600000 2 0 0 0 &cxo_clk_src>,
			<  15000000 10 0 1 4 &gpll0_out_main>,
			<  25000000 12 0 1 2 &gpll0_out_main>,
			<  50000000 12 0 0 0 &gpll0_out_main>;
	};

	blsp2_qup4_spi_apps_clk_src: blsp2_qup4_spi_apps_clk_src {
		compatible = "qcom,rcg-mn";
		qcom,base-offset = <GCC_BLSP2_QUP4_SPI_APPS_CMD_RCGR>;
		qcom,parents =
			<    0 &cxo_clk_src>,
			<    1 &gpll0_out_main>;
		qcom,supply-group = <&gcc_vdd_dig>;
		qcom,clk-fmax =
			<FMAX_LOWER 19200000>,
			<FMAX_LOW 25000000>,
			<FMAX_NOM 50000000>,
			<FMAX_TURBO 50000000>;
	};

	blsp2_qup5_i2c_apps_clk_src {
		qcom,freq-tbl =
			<   19200000 1 0 0 0 &cxo_clk_src>,
			<  50000000 12 0 0 0 &gpll0_out_main>;
	};

	blsp2_qup5_i2c_apps_clk_src: blsp2_qup5_i2c_apps_clk_src {
		compatible = "qcom,rcg-hid";
		qcom,base-offset = <GCC_BLSP2_QUP5_I2C_APPS_CMD_RCGR>;
		qcom,parents =
			<    0 &cxo_clk_src>,
			<    1 &gpll0_out_main>;
		qcom,supply-group = <&gcc_vdd_dig>;
		qcom,clk-fmax =
			<FMAX_LOWER 19200000>,
			<FMAX_LOW 50000000>,
			<FMAX_NOM 50000000>,
			<FMAX_TURBO 50000000>;
	};

	blsp2_qup5_spi_apps_clk_src {
		qcom,freq-tbl =
			<    960000 10 0 1 2 &cxo_clk_src>,
			<   4800000 4 0 0 0 &cxo_clk_src>,
			<   9600000 2 0 0 0 &cxo_clk_src>,
			<  15000000 10 0 1 4 &gpll0_out_main>,
			<  25000000 12 0 1 2 &gpll0_out_main>,
			<  50000000 12 0 0 0 &gpll0_out_main>;
	};

	blsp2_qup5_spi_apps_clk_src: blsp2_qup5_spi_apps_clk_src {
		compatible = "qcom,rcg-mn";
		qcom,base-offset = <GCC_BLSP2_QUP5_SPI_APPS_CMD_RCGR>;
		qcom,parents =
			<    0 &cxo_clk_src>,
			<    1 &gpll0_out_main>;
		qcom,supply-group = <&gcc_vdd_dig>;
		qcom,clk-fmax =
			<FMAX_LOWER 19200000>,
			<FMAX_LOW 25000000>,
			<FMAX_NOM 50000000>,
			<FMAX_TURBO 50000000>;
	};

	blsp2_qup6_i2c_apps_clk_src {
		qcom,freq-tbl =
			<   19200000 1 0 0 0 &cxo_clk_src>,
			<  50000000 12 0 0 0 &gpll0_out_main>;
	};

	blsp2_qup6_i2c_apps_clk_src: blsp2_qup6_i2c_apps_clk_src {
		compatible = "qcom,rcg-hid";
		qcom,base-offset = <GCC_BLSP2_QUP6_I2C_APPS_CMD_RCGR>;
		qcom,parents =
			<    0 &cxo_clk_src>,
			<    1 &gpll0_out_main>;
		qcom,supply-group = <&gcc_vdd_dig>;
		qcom,clk-fmax =
			<FMAX_LOWER 19200000>,
			<FMAX_LOW 50000000>,
			<FMAX_NOM 50000000>,
			<FMAX_TURBO 50000000>;
	};

	blsp2_qup6_spi_apps_clk_src {
		qcom,freq-tbl =
			<    960000 10 0 1 2 &cxo_clk_src>,
			<   4800000 4 0 0 0 &cxo_clk_src>,
			<   9600000 2 0 0 0 &cxo_clk_src>,
			<  15000000 10 0 1 4 &gpll0_out_main>,
			<  25000000 12 0 1 2 &gpll0_out_main>,
			<  50000000 12 0 0 0 &gpll0_out_main>;
	};

	blsp2_qup6_spi_apps_clk_src: blsp2_qup6_spi_apps_clk_src {
		compatible = "qcom,rcg-mn";
		qcom,base-offset = <GCC_BLSP2_QUP6_SPI_APPS_CMD_RCGR>;
		qcom,parents =
			<    0 &cxo_clk_src>,
			<    1 &gpll0_out_main>;
		qcom,supply-group = <&gcc_vdd_dig>;
		qcom,clk-fmax =
			<FMAX_LOWER 19200000>,
			<FMAX_LOW 25000000>,
			<FMAX_NOM 50000000>,
			<FMAX_TURBO 50000000>;
	};

	blsp2_uart1_apps_clk_src {
		qcom,freq-tbl =
			<   3686400 1 0 96 15625 &gpll0_out_main>,
			<   7372800 1 0 192 15625 &gpll0_out_main>,
			<  14745600 1 0 384 15625 &gpll0_out_main>,
			<  16000000 5 0 2 15 &gpll0_out_main>,
			<  24000000 5 0 1 5 &gpll0_out_main>,
			<  32000000 1 0 4 75 &gpll0_out_main>,
			<  40000000 15 0 0 0 &gpll0_out_main>,
			<  46400000 1 0 29 375 &gpll0_out_main>,
			<  48000000 12 50 0 0 &gpll0_out_main>,
			<  51200000 1 0 32 375 &gpll0_out_main>,
			<  56000000 1 0 7 75 &gpll0_out_main>,
			<  58982400 1 0 1536 15625 &gpll0_out_main>,
			<  60000000 10 0 0 0 &gpll0_out_main>,
			<  63160000 9 50 0 0 &gpll0_out_main>;
	};

	blsp2_uart1_apps_clk_src: blsp2_uart1_apps_clk_src {
		compatible = "qcom,rcg-mn";
		qcom,base-offset = <GCC_BLSP2_UART1_APPS_CMD_RCGR>;
		qcom,parents =
			<    0 &cxo_clk_src>,
			<    1 &gpll0_out_main>;
		qcom,supply-group = <&gcc_vdd_dig>;
		qcom,clk-fmax =
			<FMAX_LOWER 19200000>,
			<FMAX_LOW 31580000>,
			<FMAX_NOM 63160000>,
			<FMAX_TURBO 63160000>;
	};

	blsp2_uart2_apps_clk_src {
		qcom,freq-tbl =
			<   3686400 1 0 96 15625 &gpll0_out_main>,
			<   7372800 1 0 192 15625 &gpll0_out_main>,
			<  14745600 1 0 384 15625 &gpll0_out_main>,
			<  16000000 5 0 2 15 &gpll0_out_main>,
			<  24000000 5 0 1 5 &gpll0_out_main>,
			<  32000000 1 0 4 75 &gpll0_out_main>,
			<  40000000 15 0 0 0 &gpll0_out_main>,
			<  46400000 1 0 29 375 &gpll0_out_main>,
			<  48000000 12 50 0 0 &gpll0_out_main>,
			<  51200000 1 0 32 375 &gpll0_out_main>,
			<  56000000 1 0 7 75 &gpll0_out_main>,
			<  58982400 1 0 1536 15625 &gpll0_out_main>,
			<  60000000 10 0 0 0 &gpll0_out_main>,
			<  63160000 9 50 0 0 &gpll0_out_main>;
	};

	blsp2_uart2_apps_clk_src: blsp2_uart2_apps_clk_src {
		compatible = "qcom,rcg-mn";
		qcom,base-offset = <GCC_BLSP2_UART2_APPS_CMD_RCGR>;
		qcom,parents =
			<    0 &cxo_clk_src>,
			<    1 &gpll0_out_main>;
		qcom,supply-group = <&gcc_vdd_dig>;
		qcom,clk-fmax =
			<FMAX_LOWER 19200000>,
			<FMAX_LOW 31580000>,
			<FMAX_NOM 63160000>,
			<FMAX_TURBO 63160000>;
	};

	blsp2_uart3_apps_clk_src {
		qcom,freq-tbl =
			<   3686400 1 0 96 15625 &gpll0_out_main>,
			<   7372800 1 0 192 15625 &gpll0_out_main>,
			<  14745600 1 0 384 15625 &gpll0_out_main>,
			<  16000000 5 0 2 15 &gpll0_out_main>,
			<  24000000 5 0 1 5 &gpll0_out_main>,
			<  32000000 1 0 4 75 &gpll0_out_main>,
			<  40000000 15 0 0 0 &gpll0_out_main>,
			<  46400000 1 0 29 375 &gpll0_out_main>,
			<  48000000 12 50 0 0 &gpll0_out_main>,
			<  51200000 1 0 32 375 &gpll0_out_main>,
			<  56000000 1 0 7 75 &gpll0_out_main>,
			<  58982400 1 0 1536 15625 &gpll0_out_main>,
			<  60000000 10 0 0 0 &gpll0_out_main>,
			<  63160000 9 50 0 0 &gpll0_out_main>;
	};

	blsp2_uart3_apps_clk_src: blsp2_uart3_apps_clk_src {
		compatible = "qcom,rcg-mn";
		qcom,base-offset = <GCC_BLSP2_UART3_APPS_CMD_RCGR>;
		qcom,parents =
			<    0 &cxo_clk_src>,
			<    1 &gpll0_out_main>;
		qcom,supply-group = <&gcc_vdd_dig>;
		qcom,clk-fmax =
			<FMAX_LOWER 19200000>,
			<FMAX_LOW 31580000>,
			<FMAX_NOM 63160000>,
			<FMAX_TURBO 63160000>;
	};

	blsp2_uart4_apps_clk_src {
		qcom,freq-tbl =
			<   3686400 1 0 96 15625 &gpll0_out_main>,
			<   7372800 1 0 192 15625 &gpll0_out_main>,
			<  14745600 1 0 384 15625 &gpll0_out_main>,
			<  16000000 5 0 2 15 &gpll0_out_main>,
			<  24000000 5 0 1 5 &gpll0_out_main>,
			<  32000000 1 0 4 75 &gpll0_out_main>,
			<  40000000 15 0 0 0 &gpll0_out_main>,
			<  46400000 1 0 29 375 &gpll0_out_main>,
			<  48000000 12 50 0 0 &gpll0_out_main>,
			<  51200000 1 0 32 375 &gpll0_out_main>,
			<  56000000 1 0 7 75 &gpll0_out_main>,
			<  58982400 1 0 1536 15625 &gpll0_out_main>,
			<  60000000 10 0 0 0 &gpll0_out_main>,
			<  63160000 9 50 0 0 &gpll0_out_main>;
	};

	blsp2_uart4_apps_clk_src: blsp2_uart4_apps_clk_src {
		compatible = "qcom,rcg-mn";
		qcom,base-offset = <GCC_BLSP2_UART4_APPS_CMD_RCGR>;
		qcom,parents =
			<    0 &cxo_clk_src>,
			<    1 &gpll0_out_main>;
		qcom,supply-group = <&gcc_vdd_dig>;
		qcom,clk-fmax =
			<FMAX_LOWER 19200000>,
			<FMAX_LOW 31580000>,
			<FMAX_NOM 63160000>,
			<FMAX_TURBO 63160000>;
	};

	blsp2_uart5_apps_clk_src {
		qcom,freq-tbl =
			<   3686400 1 0 96 15625 &gpll0_out_main>,
			<   7372800 1 0 192 15625 &gpll0_out_main>,
			<  14745600 1 0 384 15625 &gpll0_out_main>,
			<  16000000 5 0 2 15 &gpll0_out_main>,
			<  24000000 5 0 1 5 &gpll0_out_main>,
			<  32000000 1 0 4 75 &gpll0_out_main>,
			<  40000000 15 0 0 0 &gpll0_out_main>,
			<  46400000 1 0 29 375 &gpll0_out_main>,
			<  48000000 12 50 0 0 &gpll0_out_main>,
			<  51200000 1 0 32 375 &gpll0_out_main>,
			<  56000000 1 0 7 75 &gpll0_out_main>,
			<  58982400 1 0 1536 15625 &gpll0_out_main>,
			<  60000000 10 0 0 0 &gpll0_out_main>,
			<  63160000 9 50 0 0 &gpll0_out_main>;
	};

	blsp2_uart5_apps_clk_src: blsp2_uart5_apps_clk_src {
		compatible = "qcom,rcg-mn";
		qcom,base-offset = <GCC_BLSP2_UART5_APPS_CMD_RCGR>;
		qcom,parents =
			<    0 &cxo_clk_src>,
			<    1 &gpll0_out_main>;
		qcom,supply-group = <&gcc_vdd_dig>;
		qcom,clk-fmax =
			<FMAX_LOWER 19200000>,
			<FMAX_LOW 31580000>,
			<FMAX_NOM 63160000>,
			<FMAX_TURBO 63160000>;
	};

	blsp2_uart6_apps_clk_src {
		qcom,freq-tbl =
			<   3686400 1 0 96 15625 &gpll0_out_main>,
			<   7372800 1 0 192 15625 &gpll0_out_main>,
			<  14745600 1 0 384 15625 &gpll0_out_main>,
			<  16000000 5 0 2 15 &gpll0_out_main>,
			<  24000000 5 0 1 5 &gpll0_out_main>,
			<  32000000 1 0 4 75 &gpll0_out_main>,
			<  40000000 15 0 0 0 &gpll0_out_main>,
			<  46400000 1 0 29 375 &gpll0_out_main>,
			<  48000000 12 50 0 0 &gpll0_out_main>,
			<  51200000 1 0 32 375 &gpll0_out_main>,
			<  56000000 1 0 7 75 &gpll0_out_main>,
			<  58982400 1 0 1536 15625 &gpll0_out_main>,
			<  60000000 10 0 0 0 &gpll0_out_main>,
			<  63160000 9 50 0 0 &gpll0_out_main>;
	};

	blsp2_uart6_apps_clk_src: blsp2_uart6_apps_clk_src {
		compatible = "qcom,rcg-mn";
		qcom,base-offset = <GCC_BLSP2_UART6_APPS_CMD_RCGR>;
		qcom,parents =
			<    0 &cxo_clk_src>,
			<    1 &gpll0_out_main>;
		qcom,supply-group = <&gcc_vdd_dig>;
		qcom,clk-fmax =
			<FMAX_LOWER 19200000>,
			<FMAX_LOW 31580000>,
			<FMAX_NOM 63160000>,
			<FMAX_TURBO 63160000>;
	};

	gp1_clk_src {
		qcom,freq-tbl =
			<  19200000 1 0 0 0 &cxo_clk_src>,
			< 100000000 6 0 0 0 &gpll0_out_main>,
			< 200000000 3 0 0 0 &gpll0_out_main>;
	};

	gp1_clk_src: gp1_clk_src {
		compatible = "qcom,rcg-mn";
		qcom,base-offset = <GCC_GP1_CMD_RCGR>;
		qcom,parents =
			<    0 &cxo_clk_src>,
			<    1 &gpll0_out_main>;
		qcom,supply-group = <&gcc_vdd_dig>;
		qcom,clk-fmax =
			<FMAX_LOWER 50000000>,
			<FMAX_LOW 100000000>,
			<FMAX_NOM 200000000>,
			<FMAX_TURBO 200000000>;
	};

	gp2_clk_src {
		qcom,freq-tbl =
			<  19200000 1 0 0 0 &cxo_clk_src>,
			< 100000000 6 0 0 0 &gpll0_out_main>,
			< 200000000 3 0 0 0 &gpll0_out_main>;
	};

	gp2_clk_src: gp2_clk_src {
		compatible = "qcom,rcg-mn";
		qcom,base-offset = <GCC_GP2_CMD_RCGR>;
		qcom,parents =
			<    0 &cxo_clk_src>,
			<    1 &gpll0_out_main>;
		qcom,supply-group = <&gcc_vdd_dig>;
		qcom,clk-fmax =
			<FMAX_LOWER 50000000>,
			<FMAX_LOW 100000000>,
			<FMAX_NOM 200000000>,
			<FMAX_TURBO 200000000>;
	};

	gp3_clk_src {
		qcom,freq-tbl =
			<  19200000 1 0 0 0 &cxo_clk_src>,
			< 100000000 6 0 0 0 &gpll0_out_main>,
			< 200000000 3 0 0 0 &gpll0_out_main>;
	};

	gp3_clk_src: gp3_clk_src {
		compatible = "qcom,rcg-mn";
		qcom,base-offset = <GCC_GP3_CMD_RCGR>;
		qcom,parents =
			<    0 &cxo_clk_src>,
			<    1 &gpll0_out_main>;
		qcom,supply-group = <&gcc_vdd_dig>;
		qcom,clk-fmax =
			<FMAX_LOWER 50000000>,
			<FMAX_LOW 100000000>,
			<FMAX_NOM 200000000>,
			<FMAX_TURBO 200000000>;
	};

	pdm2_clk_src {
		qcom,freq-tbl =
			<  60000000 10 0 0 0 &gpll0_out_main>;
	};

	pdm2_clk_src: pdm2_clk_src {
		compatible = "qcom,rcg-hid";
		qcom,base-offset = <GCC_PDM2_CMD_RCGR>;
		qcom,parents =
			<    0 &cxo_clk_src>,
			<    1 &gpll0_out_main>;
		qcom,supply-group = <&gcc_vdd_dig>;
		qcom,clk-fmax =
			<FMAX_LOWER 19200000>,
			<FMAX_LOW 60000000>,
			<FMAX_NOM 60000000>,
			<FMAX_TURBO 60000000>;
	};

	sdcc1_apps_clk_src {
		qcom,freq-tbl =
			<    144000 16 0 3 25 &cxo_clk_src>,
			<    400000 12 0 1 4 &cxo_clk_src>,
			<  20000000 15 0 1 2 &gpll0_out_main>,
			<  25000000 12 0 1 2 &gpll0_out_main>,
			<  50000000 12 0 0 0 &gpll0_out_main>,
			<  96000000 16 0 0 0 &gpll4_out_main>,
			< 192000000 8 0 0 0 &gpll4_out_main>,
			< 384000000 4 0 0 0 &gpll4_out_main>;
	};

	sdcc1_apps_clk_src: sdcc1_apps_clk_src {
		compatible = "qcom,rcg-mn";
		qcom,base-offset = <GCC_SDCC1_APPS_CMD_RCGR>;
		qcom,parents =
			<    0 &cxo_clk_src>,
			<    1 &gpll0_out_main>,
			<    5 &gpll4_out_main>;
		qcom,supply-group = <&gcc_vdd_dig>;
		qcom,clk-fmax =
			<FMAX_LOWER 19200000>,
			<FMAX_LOW 200000000>,
			<FMAX_NOM 400000000>,
			<FMAX_TURBO 400000000>;
	};

	sdcc2_apps_clk_src {
		qcom,freq-tbl =
			<    144000 16 0 3 25 &cxo_clk_src>,
			<    400000 12 0 1 4 &cxo_clk_src>,
			<  20000000 15 0 1 2 &gpll0_out_main>,
			<  25000000 12 0 1 2 &gpll0_out_main>,
			<  50000000 12 0 0 0 &gpll0_out_main>,
			< 100000000 6 0 0 0 &gpll0_out_main>,
			< 200000000 3 0 0 0 &gpll0_out_main>;
	};

	sdcc2_apps_clk_src: sdcc2_apps_clk_src {
		compatible = "qcom,rcg-mn";
		qcom,base-offset = <GCC_SDCC2_APPS_CMD_RCGR>;
		qcom,parents =
			<    0 &cxo_clk_src>,
			<    1 &gpll0_out_main>,
			<    5 &gpll4_out_main>;
		qcom,supply-group = <&gcc_vdd_dig>;
		qcom,clk-fmax =
			<FMAX_LOWER 19200000>,
			<FMAX_LOW 100000000>,
			<FMAX_NOM 200000000>,
			<FMAX_TURBO 200000000>;
	};

	sdcc3_apps_clk_src {
		qcom,freq-tbl =
			<    144000 16 0 3 25 &cxo_clk_src>,
			<    400000 12 0 1 4 &cxo_clk_src>,
			<  20000000 15 0 1 2 &gpll0_out_main>,
			<  25000000 12 0 1 2 &gpll0_out_main>,
			<  50000000 12 0 0 0 &gpll0_out_main>,
			< 100000000 6 0 0 0 &gpll0_out_main>,
			< 200000000 3 0 0 0 &gpll0_out_main>;
	};

	sdcc3_apps_clk_src: sdcc3_apps_clk_src {
		compatible = "qcom,rcg-mn";
		qcom,base-offset = <GCC_SDCC3_APPS_CMD_RCGR>;
		qcom,parents =
			<    0 &cxo_clk_src>,
			<    1 &gpll0_out_main>,
			<    5 &gpll4_out_main>;
		qcom,supply-group = <&gcc_vdd_dig>;
		qcom,clk-fmax =
			<FMAX_LOWER 19200000>,
			<FMAX_LOW 100000000>,
			<FMAX_NOM 200000000>,
			<FMAX_TURBO 200000000>;
	};

	sdcc4_apps_clk_src {
		qcom,freq-tbl =
			<    144000 16 0 3 25 &cxo_clk_src>,
			<    400000 12 0 1 4 &cxo_clk_src>,
			<  20000000 15 0 1 2 &gpll0_out_main>,
			<  25000000 12 0 1 2 &gpll0_out_main>,
			<  50000000 12 0 0 0 &gpll0_out_main>,
			< 100000000 6 0 0 0 &gpll0_out_main>;
	};

	sdcc4_apps_clk_src: sdcc4_apps_clk_src {
		compatible = "qcom,rcg-mn";
		qcom,base-offset = <GCC_SDCC4_APPS_CMD_RCGR>;
		qcom,parents =
			<    0 &cxo_clk_src>,
			<    1 &gpll0_out_main>;
		qcom,supply-group = <&gcc_vdd_dig>;
		qcom,clk-fmax =
			<FMAX_LOWER 19200000>,
			<FMAX_LOW 50000000>,
			<FMAX_NOM 100000000>,
			<FMAX_TURBO 100000000>;
	};

	tsif_ref_clk_src {
		qcom,freq-tbl =
			<    105495 1 0 1 182 &cxo_clk_src>;
	};

	tsif_ref_clk_src: tsif_ref_clk_src {
		compatible = "qcom,rcg-mn";
		qcom,base-offset = <GCC_TSIF_REF_CMD_RCGR>;
		qcom,parents =
			<    0 &cxo_clk_src>,
			<    1 &gpll0_out_main>;
		qcom,supply-group = <&gcc_vdd_dig>;
		qcom,clk-fmax =
			<FMAX_LOWER 105500>,
			<FMAX_LOW 105500>,
			<FMAX_NOM 105500>,
			<FMAX_TURBO 105500>;
	};

	usb20_mock_utmi_clk_src {
		qcom,freq-tbl =
			<  60000000 10 0 0 0 &gpll0_out_main>;
	};

	usb20_mock_utmi_clk_src: usb20_mock_utmi_clk_src {
		compatible = "qcom,rcg-hid";
		qcom,base-offset = <GCC_USB20_MOCK_UTMI_CMD_RCGR>;
		qcom,parents =
			<    0 &cxo_clk_src>,
			<    1 &gpll0_out_main>;
		qcom,supply-group = <&gcc_vdd_dig>;
		qcom,clk-fmax =
			<FMAX_LOWER 19200000>,
			<FMAX_LOW 60000000>,
			<FMAX_NOM 60000000>,
			<FMAX_TURBO 60000000>;
	};

	usb30_mock_utmi_clk_src {
		qcom,freq-tbl =
			<  60000000 10 0 0 0 &gpll0_out_main>;
	};

	usb30_mock_utmi_clk_src: usb30_mock_utmi_clk_src {
		compatible = "qcom,rcg-hid";
		qcom,base-offset = <GCC_USB30_MOCK_UTMI_CMD_RCGR>;
		qcom,parents =
			<    0 &cxo_clk_src>,
			<    1 &gpll0_out_main>;
		qcom,supply-group = <&gcc_vdd_dig>;
		qcom,clk-fmax =
			<FMAX_LOWER 40000000>,
			<FMAX_LOW 60000000>,
			<FMAX_NOM 60000000>,
			<FMAX_TURBO 60000000>;
	};

	usb3_phy_aux_clk_src {
		qcom,freq-tbl =
			<   1200000 16 0 0 0 &cxo_clk_src>;
	};

	usb3_phy_aux_clk_src: usb3_phy_aux_clk_src {
		compatible = "qcom,rcg-hid";
		qcom,base-offset = <GCC_USB3_PHY_AUX_CMD_RCGR>;
		qcom,parents =
			<    0 &cxo_clk_src>;
		qcom,supply-group = <&gcc_vdd_dig>;
		qcom,clk-fmax =
			<FMAX_LOWER 1200000>,
			<FMAX_LOW 1200000>,
			<FMAX_NOM 1200000>,
			<FMAX_TURBO 1200000>;
	};

	gcc_qusb2phy_prim_reset: gcc_qusb2phy_prim_reset {
		compatible = "qcom,reset-clk";
		qcom,base-offset = <GCC_QUSB2PHY_PRIM_BCR>;
	};

	gcc_aggre0_cnoc_ahb_clk: gcc_aggre0_cnoc_ahb_clk {
		compatible = "qcom,cbc";
		qcom,base-offset = <GCC_AGGRE0_CNOC_AHB_CBCR>;
		qcom,has-sibling;
	};

	gcc_aggre0_noc_at_clk: gcc_aggre0_noc_at_clk {
		compatible = "qcom,cbc";
		qcom,base-offset = <GCC_AGGRE0_NOC_AT_CBCR>;
		qcom,has-sibling;
	};

	gcc_aggre0_snoc_axi_clk: gcc_aggre0_snoc_axi_clk {
		compatible = "qcom,cbc";
		qcom,base-offset = <GCC_AGGRE0_SNOC_AXI_CBCR>;
		qcom,has-sibling;
	};

	gcc_pcie_0_pipe_clk: gcc_pcie_0_pipe_clk {
		compatible = "qcom,gate-clk";
		qcom,en-offset = <GCC_PCIE_0_PIPE_CBCR>;
		qcom,en-bit = <0>;
		qcom,delay = <500>;
	};

	gcc_pcie_1_pipe_clk: gcc_pcie_1_pipe_clk {
		compatible = "qcom,gate-clk";
		qcom,en-offset = <GCC_PCIE_1_PIPE_CBCR>;
		qcom,en-bit = <0>;
		qcom,delay = <500>;
	};

	gcc_blsp1_ahb_clk: gcc_blsp1_ahb_clk {
		compatible = "qcom,local-vote-clk";
		qcom,base-offset = <GCC_BLSP1_AHB_CBCR>;
		qcom,bcr-offset = <GCC_BLSP1_BCR>;
		qcom,en-offset = <GCC_APCS_CLOCK_BRANCH_ENA_VOTE>;
		qcom,en-bit = <17>;
	};

	gcc_blsp1_qup1_i2c_apps_clk: gcc_blsp1_qup1_i2c_apps_clk {
		compatible = "qcom,cbc";
		qcom,base-offset = <GCC_BLSP1_QUP1_I2C_APPS_CBCR>;
		qcom,parent = <&blsp1_qup1_i2c_apps_clk_src>;
	};

	gcc_blsp1_qup1_spi_apps_clk: gcc_blsp1_qup1_spi_apps_clk {
		compatible = "qcom,cbc";
		qcom,base-offset = <GCC_BLSP1_QUP1_SPI_APPS_CBCR>;
		qcom,parent = <&blsp1_qup1_spi_apps_clk_src>;
	};

	gcc_blsp1_qup2_i2c_apps_clk: gcc_blsp1_qup2_i2c_apps_clk {
		compatible = "qcom,cbc";
		qcom,base-offset = <GCC_BLSP1_QUP2_I2C_APPS_CBCR>;
		qcom,parent = <&blsp1_qup2_i2c_apps_clk_src>;
	};

	gcc_blsp1_qup2_spi_apps_clk: gcc_blsp1_qup2_spi_apps_clk {
		compatible = "qcom,cbc";
		qcom,base-offset = <GCC_BLSP1_QUP2_SPI_APPS_CBCR>;
		qcom,parent = <&blsp1_qup2_spi_apps_clk_src>;
	};

	gcc_blsp1_qup3_i2c_apps_clk: gcc_blsp1_qup3_i2c_apps_clk {
		compatible = "qcom,cbc";
		qcom,base-offset = <GCC_BLSP1_QUP3_I2C_APPS_CBCR>;
		qcom,parent = <&blsp1_qup3_i2c_apps_clk_src>;
	};

	gcc_blsp1_qup3_spi_apps_clk: gcc_blsp1_qup3_spi_apps_clk {
		compatible = "qcom,cbc";
		qcom,base-offset = <GCC_BLSP1_QUP3_SPI_APPS_CBCR>;
		qcom,parent = <&blsp1_qup3_spi_apps_clk_src>;
	};

	gcc_blsp1_qup4_i2c_apps_clk: gcc_blsp1_qup4_i2c_apps_clk {
		compatible = "qcom,cbc";
		qcom,base-offset = <GCC_BLSP1_QUP4_I2C_APPS_CBCR>;
		qcom,parent = <&blsp1_qup4_i2c_apps_clk_src>;
	};

	gcc_blsp1_qup4_spi_apps_clk: gcc_blsp1_qup4_spi_apps_clk {
		compatible = "qcom,cbc";
		qcom,base-offset = <GCC_BLSP1_QUP4_SPI_APPS_CBCR>;
		qcom,parent = <&blsp1_qup4_spi_apps_clk_src>;
	};

	gcc_blsp1_qup5_i2c_apps_clk: gcc_blsp1_qup5_i2c_apps_clk {
		compatible = "qcom,cbc";
		qcom,base-offset = <GCC_BLSP1_QUP5_I2C_APPS_CBCR>;
		qcom,parent = <&blsp1_qup5_i2c_apps_clk_src>;
	};

	gcc_blsp1_qup5_spi_apps_clk: gcc_blsp1_qup5_spi_apps_clk {
		compatible = "qcom,cbc";
		qcom,base-offset = <GCC_BLSP1_QUP5_SPI_APPS_CBCR>;
		qcom,parent = <&blsp1_qup5_spi_apps_clk_src>;
	};

	gcc_blsp1_qup6_i2c_apps_clk: gcc_blsp1_qup6_i2c_apps_clk {
		compatible = "qcom,cbc";
		qcom,base-offset = <GCC_BLSP1_QUP6_I2C_APPS_CBCR>;
		qcom,parent = <&blsp1_qup6_i2c_apps_clk_src>;
	};

	gcc_blsp1_qup6_spi_apps_clk: gcc_blsp1_qup6_spi_apps_clk {
		compatible = "qcom,cbc";
		qcom,base-offset = <GCC_BLSP1_QUP6_SPI_APPS_CBCR>;
		qcom,parent = <&blsp1_qup6_spi_apps_clk_src>;
	};

	gcc_blsp1_uart1_apps_clk: gcc_blsp1_uart1_apps_clk {
		compatible = "qcom,cbc";
		qcom,base-offset = <GCC_BLSP1_UART1_APPS_CBCR>;
		qcom,parent = <&blsp1_uart1_apps_clk_src>;
	};

	gcc_blsp1_uart2_apps_clk: gcc_blsp1_uart2_apps_clk {
		compatible = "qcom,cbc";
		qcom,base-offset = <GCC_BLSP1_UART2_APPS_CBCR>;
		qcom,parent = <&blsp1_uart2_apps_clk_src>;
	};

	gcc_blsp1_uart3_apps_clk: gcc_blsp1_uart3_apps_clk {
		compatible = "qcom,cbc";
		qcom,base-offset = <GCC_BLSP1_UART3_APPS_CBCR>;
		qcom,parent = <&blsp1_uart3_apps_clk_src>;
	};

	gcc_blsp1_uart4_apps_clk: gcc_blsp1_uart4_apps_clk {
		compatible = "qcom,cbc";
		qcom,base-offset = <GCC_BLSP1_UART4_APPS_CBCR>;
		qcom,parent = <&blsp1_uart4_apps_clk_src>;
	};

	gcc_blsp1_uart5_apps_clk: gcc_blsp1_uart5_apps_clk {
		compatible = "qcom,cbc";
		qcom,base-offset = <GCC_BLSP1_UART5_APPS_CBCR>;
		qcom,parent = <&blsp1_uart5_apps_clk_src>;
	};

	gcc_blsp1_uart6_apps_clk: gcc_blsp1_uart6_apps_clk {
		compatible = "qcom,cbc";
		qcom,base-offset = <GCC_BLSP1_UART6_APPS_CBCR>;
		qcom,parent = <&blsp1_uart6_apps_clk_src>;
	};

	gcc_blsp2_ahb_clk: gcc_blsp2_ahb_clk {
		compatible = "qcom,local-vote-clk";
		qcom,base-offset = <GCC_BLSP2_AHB_CBCR>;
		qcom,bcr-offset = <GCC_BLSP2_BCR>;
		qcom,en-offset = <GCC_APCS_CLOCK_BRANCH_ENA_VOTE>;
		qcom,en-bit = <15>;
	};

	gcc_blsp2_qup1_i2c_apps_clk: gcc_blsp2_qup1_i2c_apps_clk {
		compatible = "qcom,cbc";
		qcom,base-offset = <GCC_BLSP2_QUP1_I2C_APPS_CBCR>;
		qcom,parent = <&blsp2_qup1_i2c_apps_clk_src>;
	};

	gcc_blsp2_qup1_spi_apps_clk: gcc_blsp2_qup1_spi_apps_clk {
		compatible = "qcom,cbc";
		qcom,base-offset = <GCC_BLSP2_QUP1_SPI_APPS_CBCR>;
		qcom,parent = <&blsp2_qup1_spi_apps_clk_src>;
	};

	gcc_blsp2_qup2_i2c_apps_clk: gcc_blsp2_qup2_i2c_apps_clk {
		compatible = "qcom,cbc";
		qcom,base-offset = <GCC_BLSP2_QUP2_I2C_APPS_CBCR>;
		qcom,parent = <&blsp2_qup2_i2c_apps_clk_src>;
	};

	gcc_blsp2_qup2_spi_apps_clk: gcc_blsp2_qup2_spi_apps_clk {
		compatible = "qcom,cbc";
		qcom,base-offset = <GCC_BLSP2_QUP2_SPI_APPS_CBCR>;
		qcom,parent = <&blsp2_qup2_spi_apps_clk_src>;
	};

	gcc_blsp2_qup3_i2c_apps_clk: gcc_blsp2_qup3_i2c_apps_clk {
		compatible = "qcom,cbc";
		qcom,base-offset = <GCC_BLSP2_QUP3_I2C_APPS_CBCR>;
		qcom,parent = <&blsp2_qup3_i2c_apps_clk_src>;
	};

	gcc_blsp2_qup3_spi_apps_clk: gcc_blsp2_qup3_spi_apps_clk {
		compatible = "qcom,cbc";
		qcom,base-offset = <GCC_BLSP2_QUP3_SPI_APPS_CBCR>;
		qcom,parent = <&blsp2_qup3_spi_apps_clk_src>;
	};

	gcc_blsp2_qup4_i2c_apps_clk: gcc_blsp2_qup4_i2c_apps_clk {
		compatible = "qcom,cbc";
		qcom,base-offset = <GCC_BLSP2_QUP4_I2C_APPS_CBCR>;
		qcom,parent = <&blsp2_qup4_i2c_apps_clk_src>;
	};

	gcc_blsp2_qup4_spi_apps_clk: gcc_blsp2_qup4_spi_apps_clk {
		compatible = "qcom,cbc";
		qcom,base-offset = <GCC_BLSP2_QUP4_SPI_APPS_CBCR>;
		qcom,parent = <&blsp2_qup4_spi_apps_clk_src>;
	};

	gcc_blsp2_qup5_i2c_apps_clk: gcc_blsp2_qup5_i2c_apps_clk {
		compatible = "qcom,cbc";
		qcom,base-offset = <GCC_BLSP2_QUP5_I2C_APPS_CBCR>;
		qcom,parent = <&blsp2_qup5_i2c_apps_clk_src>;
	};

	gcc_blsp2_qup5_spi_apps_clk: gcc_blsp2_qup5_spi_apps_clk {
		compatible = "qcom,cbc";
		qcom,base-offset = <GCC_BLSP2_QUP5_SPI_APPS_CBCR>;
		qcom,parent = <&blsp2_qup5_spi_apps_clk_src>;
	};

	gcc_blsp2_qup6_i2c_apps_clk: gcc_blsp2_qup6_i2c_apps_clk {
		compatible = "qcom,cbc";
		qcom,base-offset = <GCC_BLSP2_QUP6_I2C_APPS_CBCR>;
		qcom,parent = <&blsp2_qup6_i2c_apps_clk_src>;
	};

	gcc_blsp2_qup6_spi_apps_clk: gcc_blsp2_qup6_spi_apps_clk {
		compatible = "qcom,cbc";
		qcom,base-offset = <GCC_BLSP2_QUP6_SPI_APPS_CBCR>;
		qcom,parent = <&blsp2_qup6_spi_apps_clk_src>;
	};

	gcc_blsp2_uart1_apps_clk: gcc_blsp2_uart1_apps_clk {
		compatible = "qcom,cbc";
		qcom,base-offset = <GCC_BLSP2_UART1_APPS_CBCR>;
		qcom,parent = <&blsp2_uart1_apps_clk_src>;
	};

	gcc_blsp2_uart2_apps_clk: gcc_blsp2_uart2_apps_clk {
		compatible = "qcom,cbc";
		qcom,base-offset = <GCC_BLSP2_UART2_APPS_CBCR>;
		qcom,parent = <&blsp2_uart2_apps_clk_src>;
	};

	gcc_blsp2_uart3_apps_clk: gcc_blsp2_uart3_apps_clk {
		compatible = "qcom,cbc";
		qcom,base-offset = <GCC_BLSP2_UART3_APPS_CBCR>;
		qcom,parent = <&blsp2_uart3_apps_clk_src>;
	};

	gcc_blsp2_uart4_apps_clk: gcc_blsp2_uart4_apps_clk {
		compatible = "qcom,cbc";
		qcom,base-offset = <GCC_BLSP2_UART4_APPS_CBCR>;
		qcom,parent = <&blsp2_uart4_apps_clk_src>;
	};

	gcc_blsp2_uart5_apps_clk: gcc_blsp2_uart5_apps_clk {
		compatible = "qcom,cbc";
		qcom,base-offset = <GCC_BLSP2_UART5_APPS_CBCR>;
		qcom,parent = <&blsp2_uart5_apps_clk_src>;
	};

	gcc_blsp2_uart6_apps_clk: gcc_blsp2_uart6_apps_clk {
		compatible = "qcom,cbc";
		qcom,base-offset = <GCC_BLSP2_UART6_APPS_CBCR>;
		qcom,parent = <&blsp2_uart6_apps_clk_src>;
	};

	gcc_boot_rom_ahb_clk: gcc_boot_rom_ahb_clk {
		compatible = "qcom,local-vote-clk";
		qcom,base-offset = <GCC_BOOT_ROM_AHB_CBCR>;
		qcom,bcr-offset = <GCC_BOOT_ROM_BCR>;
		qcom,en-offset = <GCC_APCS_CLOCK_BRANCH_ENA_VOTE>;
		qcom,en-bit = <10>;
	};

	gcc_gp1_clk: gcc_gp1_clk {
		compatible = "qcom,cbc";
		qcom,base-offset = <GCC_GP1_CBCR>;
		qcom,parent = <&gp1_clk_src>;
	};

	gcc_gp2_clk: gcc_gp2_clk {
		compatible = "qcom,cbc";
		qcom,base-offset = <GCC_GP2_CBCR>;
		qcom,parent = <&gp2_clk_src>;
	};

	gcc_gp3_clk: gcc_gp3_clk {
		compatible = "qcom,cbc";
		qcom,base-offset = <GCC_GP3_CBCR>;
		qcom,parent = <&gp3_clk_src>;
	};

	gcc_lpass_q6_axi_clk: gcc_lpass_q6_axi_clk {
		compatible = "qcom,cbc";
		qcom,base-offset = <GCC_LPASS_Q6_AXI_CBCR>;
		qcom,has-sibling;
	};

	gcc_lpass_q6_smmu_axi_clk: gcc_lpass_q6_smmu_axi_clk {
		compatible = "qcom,gate-clk";
		qcom,en-offset = <GCC_LPASS_Q6_SMMU_AXI_CBCR>;
		qcom,en-bit = <0>;
		qcom,delay = <500>;
	};

	gcc_lpass_sway_clk: gcc_lpass_sway_clk {
		compatible = "qcom,cbc";
		qcom,base-offset = <GCC_LPASS_SWAY_CBCR>;
		qcom,has-sibling;
	};

	gcc_pcie_0_aux_clk: gcc_pcie_0_aux_clk {
		compatible = "qcom,cbc";
		qcom,base-offset = <GCC_PCIE_0_AUX_CBCR>;
		qcom,has-sibling;
		qcom,parent = <&pcie_aux_clk_src>;
	};

	gcc_pcie_0_cfg_ahb_clk: gcc_pcie_0_cfg_ahb_clk {
		compatible = "qcom,cbc";
		qcom,base-offset = <GCC_PCIE_0_CFG_AHB_CBCR>;
		qcom,has-sibling;
	};

	gcc_pcie_0_mstr_axi_clk: gcc_pcie_0_mstr_axi_clk {
		compatible = "qcom,cbc";
		qcom,base-offset = <GCC_PCIE_0_MSTR_AXI_CBCR>;
		qcom,has-sibling;
	};

	gcc_pcie_0_slv_axi_clk: gcc_pcie_0_slv_axi_clk {
		compatible = "qcom,cbc";
		qcom,base-offset = <GCC_PCIE_0_SLV_AXI_CBCR>;
		qcom,has-sibling;
	};

	gcc_pcie_1_aux_clk: gcc_pcie_1_aux_clk {
		compatible = "qcom,cbc";
		qcom,base-offset = <GCC_PCIE_1_AUX_CBCR>;
		qcom,has-sibling;
		qcom,parent = <&pcie_aux_clk_src>;
	};

	gcc_pcie_1_cfg_ahb_clk: gcc_pcie_1_cfg_ahb_clk {
		compatible = "qcom,cbc";
		qcom,base-offset = <GCC_PCIE_1_CFG_AHB_CBCR>;
		qcom,has-sibling;
	};

	gcc_pcie_1_mstr_axi_clk: gcc_pcie_1_mstr_axi_clk {
		compatible = "qcom,cbc";
		qcom,base-offset = <GCC_PCIE_1_MSTR_AXI_CBCR>;
		qcom,has-sibling;
	};

	gcc_pcie_1_slv_axi_clk: gcc_pcie_1_slv_axi_clk {
		compatible = "qcom,cbc";
		qcom,base-offset = <GCC_PCIE_1_SLV_AXI_CBCR>;
		qcom,has-sibling;
	};

	gcc_pcie_2_aux_clk: gcc_pcie_2_aux_clk {
		compatible = "qcom,cbc";
		qcom,base-offset = <GCC_PCIE_2_AUX_CBCR>;
		qcom,has-sibling;
		qcom,parent = <&pcie_aux_clk_src>;
	};

	gcc_pcie_2_cfg_ahb_clk: gcc_pcie_2_cfg_ahb_clk {
		compatible = "qcom,cbc";
		qcom,base-offset = <GCC_PCIE_2_CFG_AHB_CBCR>;
		qcom,has-sibling;
	};

	gcc_pcie_2_mstr_axi_clk: gcc_pcie_2_mstr_axi_clk {
		compatible = "qcom,cbc";
		qcom,base-offset = <GCC_PCIE_2_MSTR_AXI_CBCR>;
		qcom,has-sibling;
	};

	gcc_pcie_2_pipe_clk: gcc_pcie_2_pipe_clk {
		compatible = "qcom,gate-clk";
		qcom,en-offset = <GCC_PCIE_2_PIPE_CBCR>;
		qcom,en-bit = <0>;
		qcom,delay = <500>;
	};

	gcc_pcie_2_slv_axi_clk: gcc_pcie_2_slv_axi_clk {
		compatible = "qcom,cbc";
		qcom,base-offset = <GCC_PCIE_2_SLV_AXI_CBCR>;
		qcom,has-sibling;
	};

	gcc_pcie_phy_aux_clk: gcc_pcie_phy_aux_clk {
		compatible = "qcom,cbc";
		qcom,base-offset = <GCC_PCIE_PHY_AUX_CBCR>;
		qcom,has-sibling;
		qcom,parent = <&pcie_aux_clk_src>;
	};

	gcc_pcie_phy_cfg_ahb_clk: gcc_pcie_phy_cfg_ahb_clk {
		compatible = "qcom,cbc";
		qcom,base-offset = <GCC_PCIE_PHY_CFG_AHB_CBCR>;
		qcom,has-sibling;
	};

	gcc_pdm2_clk: gcc_pdm2_clk {
		compatible = "qcom,cbc";
		qcom,base-offset = <GCC_PDM2_CBCR>;
		qcom,parent = <&pdm2_clk_src>;
	};

	gcc_pdm_ahb_clk: gcc_pdm_ahb_clk {
		compatible = "qcom,cbc";
		qcom,base-offset = <GCC_PDM_AHB_CBCR>;
		qcom,has-sibling;
	};

	gcc_prng_ahb_clk: gcc_prng_ahb_clk {
		compatible = "qcom,local-vote-clk";
		qcom,base-offset = <GCC_PRNG_AHB_CBCR>;
		qcom,bcr-offset = <GCC_PRNG_BCR>;
		qcom,en-offset = <GCC_APCS_CLOCK_BRANCH_ENA_VOTE>;
		qcom,en-bit = <13>;
	};

	gcc_sdcc1_ahb_clk: gcc_sdcc1_ahb_clk {
		compatible = "qcom,cbc";
		qcom,base-offset = <GCC_SDCC1_AHB_CBCR>;
		qcom,has-sibling;
	};

	gcc_sdcc1_apps_clk: gcc_sdcc1_apps_clk {
		compatible = "qcom,cbc";
		qcom,base-offset = <GCC_SDCC1_APPS_CBCR>;
		qcom,parent = <&sdcc1_apps_clk_src>;
	};

	gcc_sdcc2_ahb_clk: gcc_sdcc2_ahb_clk {
		compatible = "qcom,cbc";
		qcom,base-offset = <GCC_SDCC2_AHB_CBCR>;
		qcom,has-sibling;
	};

	gcc_sdcc2_apps_clk: gcc_sdcc2_apps_clk {
		compatible = "qcom,cbc";
		qcom,base-offset = <GCC_SDCC2_APPS_CBCR>;
		qcom,parent = <&sdcc2_apps_clk_src>;
	};

	gcc_sdcc3_ahb_clk: gcc_sdcc3_ahb_clk {
		compatible = "qcom,cbc";
		qcom,base-offset = <GCC_SDCC3_AHB_CBCR>;
		qcom,has-sibling;
	};

	gcc_sdcc3_apps_clk: gcc_sdcc3_apps_clk {
		compatible = "qcom,cbc";
		qcom,base-offset = <GCC_SDCC3_APPS_CBCR>;
		qcom,parent = <&sdcc3_apps_clk_src>;
	};

	gcc_sdcc4_ahb_clk: gcc_sdcc4_ahb_clk {
		compatible = "qcom,cbc";
		qcom,base-offset = <GCC_SDCC4_AHB_CBCR>;
		qcom,has-sibling;
	};

	gcc_sdcc4_apps_clk: gcc_sdcc4_apps_clk {
		compatible = "qcom,cbc";
		qcom,base-offset = <GCC_SDCC4_APPS_CBCR>;
		qcom,parent = <&sdcc4_apps_clk_src>;
	};

	gcc_sys_noc_hs_axi_clk: gcc_sys_noc_hs_axi_clk {
		compatible = "qcom,cbc";
		qcom,base-offset = <GCC_SYS_NOC_HS_AXI_CBCR>;
		qcom,has-sibling;
	};

	gcc_sys_noc_ufs_axi_clk: gcc_sys_noc_ufs_axi_clk {
		compatible = "qcom,cbc";
		qcom,base-offset = <GCC_SYS_NOC_UFS_AXI_CBCR>;
		qcom,has-sibling;
		qcom,parent = <&ufs_axi_clk_src>;
	};

	gcc_sys_noc_usb3_axi_clk: gcc_sys_noc_usb3_axi_clk {
		compatible = "qcom,cbc";
		qcom,base-offset = <GCC_SYS_NOC_USB3_AXI_CBCR>;
		qcom,has-sibling;
		qcom,parent = <&usb30_master_clk_src>;
	};

	gcc_tsif_ahb_clk: gcc_tsif_ahb_clk {
		compatible = "qcom,cbc";
		qcom,base-offset = <GCC_TSIF_AHB_CBCR>;
		qcom,has-sibling;
	};

	gcc_tsif_ref_clk: gcc_tsif_ref_clk {
		compatible = "qcom,cbc";
		qcom,base-offset = <GCC_TSIF_REF_CBCR>;
		qcom,parent = <&tsif_ref_clk_src>;
	};

	gcc_ufs_ahb_clk: gcc_ufs_ahb_clk {
		compatible = "qcom,cbc";
		qcom,base-offset = <GCC_UFS_AHB_CBCR>;
		qcom,has-sibling;
	};

	gcc_ufs_axi_clk: gcc_ufs_axi_clk {
		compatible = "qcom,cbc";
		qcom,base-offset = <GCC_UFS_AXI_CBCR>;
		qcom,parent = <&ufs_axi_clk_src>;
	};

	gcc_ufs_ice_core_clk: gcc_ufs_ice_core_clk {
		compatible = "qcom,cbc";
		qcom,base-offset = <GCC_UFS_ICE_CORE_CBCR>;
		qcom,has-sibling;
		qcom,parent = <&ufs_ice_core_clk_src>;
	};

	gcc_ufs_rx_cfg_branch_clk: gcc_ufs_rx_cfg_branch_clk {
		compatible = "qcom,cbc";
		qcom,base-offset = <GCC_UFS_RX_CFG_CBCR>;
		qcom,has-sibling;
		qcom,parent = <&ufs_axi_clk_src>;
	};

	gcc_ufs_rx_cfg_clk: gcc_ufs_rx_cfg_clk {
		compatible = "qcom,fixed-div-clk";
		qcom,div = <16>;
		qcom,slave-div;
		qcom,parent = <&gcc_ufs_rx_cfg_branch_clk>;
	};

	gcc_ufs_rx_symbol_0_clk: gcc_ufs_rx_symbol_0_clk {
		compatible = "qcom,gate-clk";
		qcom,en-offset = <GCC_UFS_RX_SYMBOL_0_CBCR>;
		qcom,en-bit = <0>;
		qcom,delay = <500>;
	};

	gcc_ufs_rx_symbol_1_clk: gcc_ufs_rx_symbol_1_clk {
		compatible = "qcom,cbc";
		qcom,base-offset = <GCC_UFS_RX_SYMBOL_1_CBCR>;
		qcom,has-sibling;
	};

	gcc_ufs_tx_cfg_branch_clk: gcc_ufs_tx_cfg_branch_clk {
		compatible = "qcom,cbc";
		qcom,base-offset = <GCC_UFS_TX_CFG_CBCR>;
		qcom,has-sibling;
		qcom,parent = <&ufs_axi_clk_src>;
	};

	gcc_ufs_tx_cfg_clk: gcc_ufs_tx_cfg_clk {
		compatible = "qcom,fixed-div-clk";
		qcom,div = <16>;
		qcom,slave-div;
		qcom,parent = <&gcc_ufs_tx_cfg_branch_clk>;
	};

	gcc_ufs_tx_symbol_0_clk: gcc_ufs_tx_symbol_0_clk {
		compatible = "qcom,gate-clk";
		qcom,en-offset = <GCC_UFS_TX_SYMBOL_0_CBCR>;
		qcom,en-bit = <0>;
		qcom,delay = <500>;
	};

	gcc_ufs_ice_core_postdiv_clk_src: gcc_ufs_ice_core_postdiv_clk_src {
		compatible = "qcom,fixed-div-clk";
		qcom,div = <2>;
		qcom,parent = <&ufs_ice_core_clk_src>;
	};

	gcc_ufs_unipro_core_clk: gcc_ufs_unipro_core_clk {
		compatible = "qcom,cbc";
		qcom,base-offset = <GCC_UFS_UNIPRO_CORE_CBCR>;
		qcom,has-sibling;
		qcom,parent = <&gcc_ufs_ice_core_postdiv_clk_src>;
	};

	gcc_usb3_phy_pipe_clk: gcc_usb3_phy_pipe_clk {
		compatible = "qcom,cbc";
		qcom,base-offset = <GCC_USB3_PHY_PIPE_CBCR>;
		qcom,bcr-offset = <GCC_USB3PHY_PHY_BCR>;
		qcom,has-sibling;
	};

	gcc_usb20_master_clk: gcc_usb20_master_clk {
		compatible = "qcom,cbc";
		qcom,base-offset = <GCC_USB20_MASTER_CBCR>;
		qcom,has-sibling;
		qcom,parent = <&usb20_master_clk_src>;
	};

	gcc_usb20_mock_utmi_clk: gcc_usb20_mock_utmi_clk {
		compatible = "qcom,cbc";
		qcom,base-offset = <GCC_USB20_MOCK_UTMI_CBCR>;
		qcom,parent = <&usb20_mock_utmi_clk_src>;
	};

	gcc_usb20_sleep_clk: gcc_usb20_sleep_clk {
		compatible = "qcom,cbc";
		qcom,base-offset = <GCC_USB20_SLEEP_CBCR>;
		qcom,has-sibling;
	};

	gcc_usb30_master_clk: gcc_usb30_master_clk {
		compatible = "qcom,cbc";
		qcom,base-offset = <GCC_USB30_MASTER_CBCR>;
		qcom,bcr-offset = <GCC_USB_30_BCR>;
		qcom,parent = <&usb30_master_clk_src>;
		qcom,depends = <&gcc_sys_noc_usb3_axi_clk>;
	};

	gcc_usb30_mock_utmi_clk: gcc_usb30_mock_utmi_clk {
		compatible = "qcom,cbc";
		qcom,base-offset = <GCC_USB30_MOCK_UTMI_CBCR>;
		qcom,parent = <&usb30_mock_utmi_clk_src>;
	};

	gcc_usb30_sleep_clk: gcc_usb30_sleep_clk {
		compatible = "qcom,cbc";
		qcom,base-offset = <GCC_USB30_SLEEP_CBCR>;
		qcom,has-sibling;
	};

	gcc_usb3_phy_aux_clk: gcc_usb3_phy_aux_clk {
		compatible = "qcom,cbc";
		qcom,base-offset = <GCC_USB3_PHY_AUX_CBCR>;
		qcom,parent = <&usb3_phy_aux_clk_src>;
	};

	gcc_usb_phy_cfg_ahb2phy_clk: gcc_usb_phy_cfg_ahb2phy_clk {
		compatible = "qcom,cbc";
		qcom,base-offset = <GCC_USB_PHY_CFG_AHB2PHY_CBCR>;
		qcom,has-sibling;
	};

	gcc_debug_mux: gcc_debug_mux {
		compatible = "qcom,measure-mux";
		qcom,offset = <GCC_GCC_DEBUG_CLK_CTL>;
		qcom,mask = <0x3FF>;
		qcom,shift = <0>;
		qcom,en-offset = <GCC_GCC_DEBUG_CLK_CTL>;
		qcom,en-mask = <0x10000>;
		qcom,parents =
			<0x000e &cnoc_clk>,
			<0x0011 &pnoc_clk>,
			<0x0000 &snoc_clk>,
			<0x00ad &bimc_clk>,
			<0x001c &gcc_mmss_bimc_gfx_m_clk>,
			<0x0099 &ce1_clk>,
			<0x009a &gcc_ce1_axi_m_clk>,
			<0x009b &gcc_ce1_ahb_m_clk>,
			<0x0006 &gcc_sys_noc_usb3_axi_clk>,
			<0x0007 &gcc_sys_noc_ufs_axi_clk>,
			<0x000a &gcc_sys_noc_hs_axi_clk>,
			<0x002d &gcc_usb30_master_clk>,
			<0x002e &gcc_usb30_sleep_clk>,
			<0x002f &gcc_usb30_mock_utmi_clk>,
			<0x0030 &gcc_usb3_phy_aux_clk>,
			<0x0031 &gcc_usb3_phy_pipe_clk>,
			<0x0035 &gcc_usb20_master_clk>,
			<0x0036 &gcc_usb20_sleep_clk>,
			<0x0037 &gcc_usb20_mock_utmi_clk>,
			<0x0038 &gcc_usb_phy_cfg_ahb2phy_clk>,
			<0x0039 &gcc_sdcc1_apps_clk>,
			<0x003a &gcc_sdcc1_ahb_clk>,
			<0x003b &gcc_sdcc2_apps_clk>,
			<0x003c &gcc_sdcc2_ahb_clk>,
			<0x003d &gcc_sdcc3_apps_clk>,
			<0x003e &gcc_sdcc3_ahb_clk>,
			<0x003f &gcc_sdcc4_apps_clk>,
			<0x0040 &gcc_sdcc4_ahb_clk>,
			<0x0041 &gcc_blsp1_ahb_clk>,
			<0x0043 &gcc_blsp1_qup1_spi_apps_clk>,
			<0x0044 &gcc_blsp1_qup1_i2c_apps_clk>,
			<0x0045 &gcc_blsp1_uart1_apps_clk>,
			<0x0047 &gcc_blsp1_qup2_spi_apps_clk>,
			<0x0048 &gcc_blsp1_qup2_i2c_apps_clk>,
			<0x0049 &gcc_blsp1_uart2_apps_clk>,
			<0x004b &gcc_blsp1_qup3_spi_apps_clk>,
			<0x004c &gcc_blsp1_qup3_i2c_apps_clk>,
			<0x004d &gcc_blsp1_uart3_apps_clk>,
			<0x004f &gcc_blsp1_qup4_spi_apps_clk>,
			<0x0050 &gcc_blsp1_qup4_i2c_apps_clk>,
			<0x0051 &gcc_blsp1_uart4_apps_clk>,
			<0x0053 &gcc_blsp1_qup5_spi_apps_clk>,
			<0x0054 &gcc_blsp1_qup5_i2c_apps_clk>,
			<0x0055 &gcc_blsp1_uart5_apps_clk>,
			<0x0057 &gcc_blsp1_qup6_spi_apps_clk>,
			<0x0058 &gcc_blsp1_qup6_i2c_apps_clk>,
			<0x0059 &gcc_blsp1_uart6_apps_clk>,
			<0x005b &gcc_blsp2_ahb_clk>,
			<0x005d &gcc_blsp2_qup1_spi_apps_clk>,
			<0x005e &gcc_blsp2_qup1_i2c_apps_clk>,
			<0x005f &gcc_blsp2_uart1_apps_clk>,
			<0x0061 &gcc_blsp2_qup2_spi_apps_clk>,
			<0x0062 &gcc_blsp2_qup2_i2c_apps_clk>,
			<0x0063 &gcc_blsp2_uart2_apps_clk>,
			<0x0065 &gcc_blsp2_qup3_spi_apps_clk>,
			<0x0066 &gcc_blsp2_qup3_i2c_apps_clk>,
			<0x0067 &gcc_blsp2_uart3_apps_clk>,
			<0x0069 &gcc_blsp2_qup4_spi_apps_clk>,
			<0x006a &gcc_blsp2_qup4_i2c_apps_clk>,
			<0x006b &gcc_blsp2_uart4_apps_clk>,
			<0x006d &gcc_blsp2_qup5_spi_apps_clk>,
			<0x006e &gcc_blsp2_qup5_i2c_apps_clk>,
			<0x006f &gcc_blsp2_uart5_apps_clk>,
			<0x0071 &gcc_blsp2_qup6_spi_apps_clk>,
			<0x0072 &gcc_blsp2_qup6_i2c_apps_clk>,
			<0x0073 &gcc_blsp2_uart6_apps_clk>,
			<0x0076 &gcc_pdm_ahb_clk>,
			<0x0078 &gcc_pdm2_clk>,
			<0x0079 &gcc_prng_ahb_clk>,
			<0x007a &gcc_tsif_ahb_clk>,
			<0x007b &gcc_tsif_ref_clk>,
			<0x007e &gcc_boot_rom_ahb_clk>,
			<0x00b0 &gcc_lpass_q6_axi_clk>,
			<0x00b1 &gcc_lpass_q6_smmu_axi_clk>,
			<0x00b2 &gcc_lpass_sway_clk>,
			<0x00e3 &gcc_gp1_clk>,
			<0x00e4 &gcc_gp2_clk>,
			<0x00e5 &gcc_gp3_clk>,
			<0x00e6 &gcc_pcie_0_slv_axi_clk>,
			<0x00e7 &gcc_pcie_0_mstr_axi_clk>,
			<0x00e8 &gcc_pcie_0_cfg_ahb_clk>,
			<0x00e9 &gcc_pcie_0_aux_clk>,
			<0x00ea &gcc_pcie_0_pipe_clk>,
			<0x00ec &gcc_pcie_1_slv_axi_clk>,
			<0x00ed &gcc_pcie_1_mstr_axi_clk>,
			<0x00ee &gcc_pcie_1_cfg_ahb_clk>,
			<0x00ef &gcc_pcie_1_aux_clk>,
			<0x00f0 &gcc_pcie_1_pipe_clk>,
			<0x00f2 &gcc_pcie_2_slv_axi_clk>,
			<0x00f3 &gcc_pcie_2_mstr_axi_clk>,
			<0x00f4 &gcc_pcie_2_cfg_ahb_clk>,
			<0x00f5 &gcc_pcie_2_aux_clk>,
			<0x00f6 &gcc_pcie_2_pipe_clk>,
			<0x00f8 &gcc_pcie_phy_cfg_ahb_clk>,
			<0x00f9 &gcc_pcie_phy_aux_clk>,
			<0x00fc &gcc_ufs_axi_clk>,
			<0x00fd &gcc_ufs_ahb_clk>,
			<0x00fe &gcc_ufs_tx_cfg_clk>,
			<0x00ff &gcc_ufs_rx_cfg_clk>,
			<0x0100 &gcc_ufs_tx_symbol_0_clk>,
			<0x0101 &gcc_ufs_rx_symbol_0_clk>,
			<0x0102 &gcc_ufs_rx_symbol_1_clk>,
			<0x0106 &gcc_ufs_unipro_core_clk>,
			<0x0107 &gcc_ufs_ice_core_clk>,
			<0x0116 &gcc_aggre0_snoc_axi_clk>,
			<0x0117 &gcc_aggre0_cnoc_ahb_clk>,
			<0x0118 &gcc_aggre0_noc_at_clk>;
		qcom,recursive-parents = <&gcc_mmss_gcc_dbg_clk>;
		qcom,cxo = <&cxo_clk_src>;
		qcom,xo-div4-cbcr = <GCC_GCC_XO_DIV4_CBCR>;
		qcom,test-pad-config = <0x51A00>;
		qcom,clk-flags = <0xC000>;
	};
};
